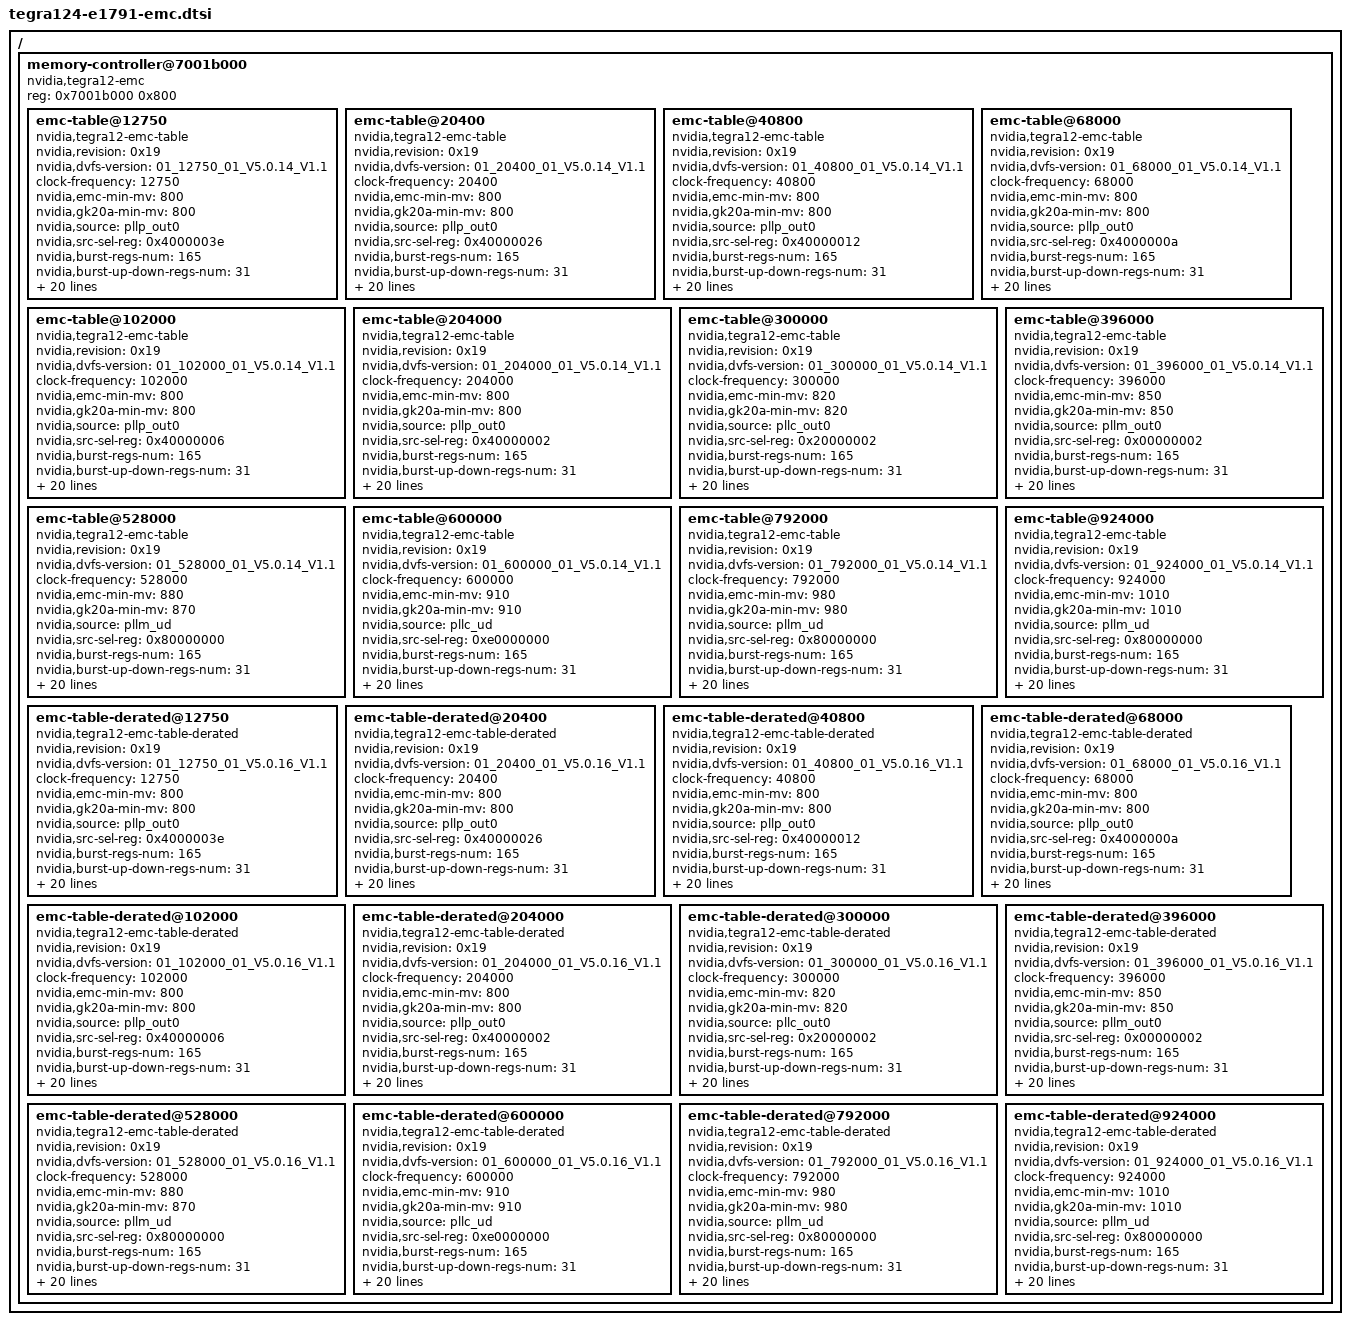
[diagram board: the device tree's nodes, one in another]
/ {
memory-controller@7001b000 {
		compatible = "nvidia,tegra12-emc";
		reg = <0x7001b000 0x800>;
		#address-cells = <1>;
		#size-cells = <0>;
		emc-table@12750 {
			compatible = "nvidia,tegra12-emc-table";
			nvidia,revision = <0x19>;
			nvidia,dvfs-version = "01_12750_01_V5.0.14_V1.1";
			clock-frequency = <12750>;
			nvidia,emc-min-mv = <800>;
			nvidia,gk20a-min-mv = <800>;
			nvidia,source = "pllp_out0";
			nvidia,src-sel-reg = <0x4000003e>;
			nvidia,burst-regs-num = <165>;
			nvidia,burst-up-down-regs-num = <31>;
			nvidia,emc-registers = <
				0x00000000
				0x00000003
				0x00000000
				0x00000002
				0x00000002
				0x00000006
				0x00000008
				0x00000003
				0x0000000a
				0x00000002
				0x00000002
				0x00000001
				0x00000002
				0x00000000
				0x00000003
				0x00000003
				0x00000006
				0x00000002
				0x00000000
				0x00000005
				0x00000005
				0x00010000
				0x00000003
				0x00000000
				0x00000000
				0x00000000
				0x00000000
				0x00000004
				0x0000000c
				0x0000000d
				0x0000000f
				0x00000030
				0x00000000
				0x0000000c
				0x00000002
				0x00000002
				0x00000002
				0x00000000
				0x00000001
				0x0000000c
				0x00000003
				0x00000002
				0x00000003
				0x00000003
				0x00000003
				0x00000006
				0x00000004
				0x00000003
				0x00000003
				0x00000036
				0x00000000
				0x00000000
				0x00000000
				0x1363a296
				0x005800a0
				0x00008000
				0x00048000
				0x00048000
				0x00048000
				0x00048000
				0x00048000
				0x00048000
				0x00048000
				0x00048000
				0x00048000
				0x00048000
				0x00048000
				0x00048000
				0x00048000
				0x00048000
				0x00048000
				0x00048000
				0x00000000
				0x00000000
				0x00000000
				0x00000000
				0x00000000
				0x00000000
				0x00000000
				0x00000000
				0x000fc000
				0x000fc000
				0x00000000
				0x000fc000
				0x000fc000
				0x00000000
				0x00000000
				0x00000000
				0x00000000
				0x00000000
				0x00000000
				0x00000000
				0x00000000
				0x00000000
				0x00000000
				0x00000000
				0x00000000
				0x00000000
				0x00000000
				0x00000000
				0x00000000
				0x00000000
				0x00000000
				0x00000000
				0x00000000
				0x00000000
				0x00000000
				0x00000000
				0x00000000
				0x00000000
				0x000fc000
				0x000fc000
				0x0002c000
				0x000fc000
				0x0000fc00
				0x0000fc00
				0x0000fc00
				0x0000fc00
				0x00000200
				0x00000000
				0x00100100
				0x0130b018
				0x00000000
				0x00000000
				0x77ffc000
				0x00000e0e
				0x81f1f008
				0x07070000
				0x0000003f
				0x015ddddd
				0x51451400
				0x00514514
				0x00514514
				0x51451400
				0x0000003f
				0x00000000
				0x00000000
				0x00064000
				0x00000011
				0x000d0011
				0x000d0011
				0x00000000
				0x00000003
				0x0000f3f3
				0x80000164
				0x0000000a
				0x40040001
				0x8000000a
				0x00000001
				0x00000001
				0x00000002
				0x00000000
				0x00000003
				0x00000001
				0x00000002
				0x00000007
				0x00000002
				0x00000001
				0x00000004
				0x00000005
				0x05040102
				0x00090402
				0x77c30303
				0x70000f03
				0x001f0000
			>;
			nvidia,emc-burst-up-down-regs = <
			0x00000001
			0x00000007
			0x00ff00ff
			0x00ff00ff
			0x00ff00ff
			0x00ff00ff
			0x00ff00ff
			0x00ff00ff
			0x00ff00ff
			0x00ff0049
			0x00ff0080
			0x00ff0004
			0x00ff0004
			0x000800ff
			0x000000ff
			0x00ff0004
			0x00ff00ff
			0x00ff00ff
			0x00ff0024
			0x00ff00ff
			0x000000ff
			0x000000ff
			0x00ff00ff
			0x000000ff
			0x00ff00ff
			0x00ff00ff
			0x00ff00ff
			0x00ff00ff
			0x00ff00ff
			0x00ff00ff
			0x00ff00ff
			>;
			nvidia,emc-zcal-cnt-long = <0x00000015>;
			nvidia,emc-acal-interval = <0x001fffff>;
			nvidia,emc-ctt-term_ctrl = <0x00000802>;
			nvidia,emc-cfg = <0xf3200000>;
			nvidia,emc-cfg-2 = <0x000008c7>;
			nvidia,emc-sel-dpd-ctrl = <0x0004013c>;
			nvidia,emc-cfg-dig-dll = <0x00580068>;
			nvidia,emc-bgbias-ctl0 = <0x00000008>;
			nvidia,emc-auto-cal-config2 = <0x00000000>;
			nvidia,emc-auto-cal-config3 = <0x00000000>;
			nvidia,emc-auto-cal-config = <0xa1430000>;
			nvidia,emc-mode-0 = <0x00000000>;
			nvidia,emc-mode-1 = <0x00010083>;
			nvidia,emc-mode-2 = <0x00020004>;
			nvidia,emc-mode-4 = <0x800b0000>;
			nvidia,emc-clock-latency-change = <57820>;
		};
		emc-table@20400 {
			compatible = "nvidia,tegra12-emc-table";
			nvidia,revision = <0x19>;
			nvidia,dvfs-version = "01_20400_01_V5.0.14_V1.1";
			clock-frequency = <20400>;
			nvidia,emc-min-mv = <800>;
			nvidia,gk20a-min-mv = <800>;
			nvidia,source = "pllp_out0";
			nvidia,src-sel-reg = <0x40000026>;
			nvidia,burst-regs-num = <165>;
			nvidia,burst-up-down-regs-num = <31>;
			nvidia,emc-registers = <
				0x00000001
				0x00000003
				0x00000000
				0x00000002
				0x00000002
				0x00000006
				0x00000008
				0x00000003
				0x0000000a
				0x00000002
				0x00000002
				0x00000001
				0x00000002
				0x00000000
				0x00000003
				0x00000003
				0x00000006
				0x00000002
				0x00000000
				0x00000005
				0x00000005
				0x00010000
				0x00000003
				0x00000000
				0x00000000
				0x00000000
				0x00000000
				0x00000004
				0x0000000c
				0x0000000d
				0x0000000f
				0x0000004d
				0x00000000
				0x00000013
				0x00000002
				0x00000002
				0x00000002
				0x00000000
				0x00000001
				0x0000000c
				0x00000003
				0x00000003
				0x00000003
				0x00000003
				0x00000003
				0x00000006
				0x00000004
				0x00000003
				0x00000003
				0x00000055
				0x00000000
				0x00000000
				0x00000000
				0x1363a296
				0x005800a0
				0x00008000
				0x00048000
				0x00048000
				0x00048000
				0x00048000
				0x00048000
				0x00048000
				0x00048000
				0x00048000
				0x00048000
				0x00048000
				0x00048000
				0x00048000
				0x00048000
				0x00048000
				0x00048000
				0x00048000
				0x00000000
				0x00000000
				0x00000000
				0x00000000
				0x00000000
				0x00000000
				0x00000000
				0x00000000
				0x000fc000
				0x000fc000
				0x00000000
				0x000fc000
				0x000fc000
				0x00000000
				0x00000000
				0x00000000
				0x00000000
				0x00000000
				0x00000000
				0x00000000
				0x00000000
				0x00000000
				0x00000000
				0x00000000
				0x00000000
				0x00000000
				0x00000000
				0x00000000
				0x00000000
				0x00000000
				0x00000000
				0x00000000
				0x00000000
				0x00000000
				0x00000000
				0x00000000
				0x00000000
				0x00000000
				0x000fc000
				0x000fc000
				0x0002c000
				0x000fc000
				0x0000fc00
				0x0000fc00
				0x0000fc00
				0x0000fc00
				0x00000200
				0x00000000
				0x00100100
				0x0130b018
				0x00000000
				0x00000000
				0x77ffc000
				0x00000e0e
				0x81f1f008
				0x07070000
				0x0000003f
				0x015ddddd
				0x51451400
				0x00514514
				0x00514514
				0x51451400
				0x0000003f
				0x00000000
				0x00000000
				0x00064000
				0x00000011
				0x00150011
				0x00150011
				0x00000000
				0x00000003
				0x0000f3f3
				0x8000019f
				0x0000000a
				0x40020001
				0x80000012
				0x00000001
				0x00000001
				0x00000002
				0x00000000
				0x00000003
				0x00000001
				0x00000002
				0x00000007
				0x00000002
				0x00000001
				0x00000004
				0x00000005
				0x05040102
				0x00090402
				0x74e30303
				0x70000f03
				0x001f0000
			>;
			nvidia,emc-burst-up-down-regs = <
			0x00000001
			0x0000000a
			0x00ff00ff
			0x00ff00ff
			0x00ff00ff
			0x00ff00ff
			0x00ff00ff
			0x00ff00ff
			0x00ff00ff
			0x00ff0049
			0x00ff0080
			0x00ff0004
			0x00ff0004
			0x000800ff
			0x000000ff
			0x00ff0004
			0x00ff00ff
			0x00ff00ff
			0x00ff0024
			0x00ff00ff
			0x000000ff
			0x000000ff
			0x00ff00ff
			0x000000ff
			0x00ff00ff
			0x00ff00ff
			0x00ff00ff
			0x00ff00ff
			0x00ff00ff
			0x00ff00ff
			0x00ff00ff
			>;
			nvidia,emc-zcal-cnt-long = <0x00000015>;
			nvidia,emc-acal-interval = <0x001fffff>;
			nvidia,emc-ctt-term_ctrl = <0x00000802>;
			nvidia,emc-cfg = <0xf3200000>;
			nvidia,emc-cfg-2 = <0x000008c7>;
			nvidia,emc-sel-dpd-ctrl = <0x0004013c>;
			nvidia,emc-cfg-dig-dll = <0x00580068>;
			nvidia,emc-bgbias-ctl0 = <0x00000008>;
			nvidia,emc-auto-cal-config2 = <0x00000000>;
			nvidia,emc-auto-cal-config3 = <0x00000000>;
			nvidia,emc-auto-cal-config = <0xa1430000>;
			nvidia,emc-mode-0 = <0x00000000>;
			nvidia,emc-mode-1 = <0x00010083>;
			nvidia,emc-mode-2 = <0x00020004>;
			nvidia,emc-mode-4 = <0x800b0000>;
			nvidia,emc-clock-latency-change = <35610>;
		};
		emc-table@40800 {
			compatible = "nvidia,tegra12-emc-table";
			nvidia,revision = <0x19>;
			nvidia,dvfs-version = "01_40800_01_V5.0.14_V1.1";
			clock-frequency = <40800>;
			nvidia,emc-min-mv = <800>;
			nvidia,gk20a-min-mv = <800>;
			nvidia,source = "pllp_out0";
			nvidia,src-sel-reg = <0x40000012>;
			nvidia,burst-regs-num = <165>;
			nvidia,burst-up-down-regs-num = <31>;
			nvidia,emc-registers = <
				0x00000002
				0x00000005
				0x00000000
				0x00000002
				0x00000002
				0x00000006
				0x00000008
				0x00000003
				0x0000000a
				0x00000002
				0x00000002
				0x00000001
				0x00000002
				0x00000000
				0x00000003
				0x00000003
				0x00000006
				0x00000002
				0x00000000
				0x00000005
				0x00000005
				0x00010000
				0x00000003
				0x00000000
				0x00000000
				0x00000000
				0x00000000
				0x00000004
				0x0000000c
				0x0000000d
				0x0000000f
				0x0000009a
				0x00000000
				0x00000026
				0x00000002
				0x00000002
				0x00000002
				0x00000000
				0x00000001
				0x0000000c
				0x00000006
				0x00000006
				0x00000003
				0x00000003
				0x00000003
				0x00000006
				0x00000004
				0x00000003
				0x00000003
				0x000000aa
				0x00000000
				0x00000000
				0x00000000
				0x1363a296
				0x005800a0
				0x00008000
				0x00048000
				0x00048000
				0x00048000
				0x00048000
				0x00048000
				0x00048000
				0x00048000
				0x00048000
				0x00048000
				0x00048000
				0x00048000
				0x00048000
				0x00048000
				0x00048000
				0x00048000
				0x00048000
				0x00000000
				0x00000000
				0x00000000
				0x00000000
				0x00000000
				0x00000000
				0x00000000
				0x00000000
				0x000fc000
				0x000fc000
				0x00000000
				0x000fc000
				0x000fc000
				0x00000000
				0x00000000
				0x00000000
				0x00000000
				0x00000000
				0x00000000
				0x00000000
				0x00000000
				0x00000000
				0x00000000
				0x00000000
				0x00000000
				0x00000000
				0x00000000
				0x00000000
				0x00000000
				0x00000000
				0x00000000
				0x00000000
				0x00000000
				0x00000000
				0x00000000
				0x00000000
				0x00000000
				0x00000000
				0x000fc000
				0x000fc000
				0x0002c000
				0x000fc000
				0x0000fc00
				0x0000fc00
				0x0000fc00
				0x0000fc00
				0x00000200
				0x00000000
				0x00100100
				0x0130b018
				0x00000000
				0x00000000
				0x77ffc000
				0x00000e0e
				0x81f1f008
				0x07070000
				0x0000003f
				0x015ddddd
				0x51451400
				0x00514514
				0x00514514
				0x51451400
				0x0000003f
				0x00000000
				0x00000000
				0x00064000
				0x00000011
				0x00290011
				0x00290011
				0x00000000
				0x00000003
				0x0000f3f3
				0x8000023a
				0x0000000a
				0xa0000001
				0x80000017
				0x00000001
				0x00000001
				0x00000002
				0x00000000
				0x00000003
				0x00000001
				0x00000002
				0x00000007
				0x00000002
				0x00000001
				0x00000004
				0x00000005
				0x05040102
				0x00090402
				0x73030303
				0x70000f03
				0x001f0000
			>;
			nvidia,emc-burst-up-down-regs = <
			0x00000001
			0x00000014
			0x00ff00ff
			0x00ff00ff
			0x00ff00ff
			0x00ff00ff
			0x00ff00ff
			0x00ff00ff
			0x00ff00ff
			0x00ff0049
			0x00ff0080
			0x00ff0004
			0x00ff0004
			0x000800ff
			0x000000ff
			0x00ff0004
			0x00ff00ff
			0x00ff00ff
			0x00ff0024
			0x00ff00ff
			0x000000ff
			0x000000ff
			0x00ff00ff
			0x000000ff
			0x00ff00ff
			0x00ff00ff
			0x00ff00ff
			0x00ff00ff
			0x00ff00ff
			0x00ff00ff
			0x00ff00ff
			>;
			nvidia,emc-zcal-cnt-long = <0x00000015>;
			nvidia,emc-acal-interval = <0x001fffff>;
			nvidia,emc-ctt-term_ctrl = <0x00000802>;
			nvidia,emc-cfg = <0xf3200000>;
			nvidia,emc-cfg-2 = <0x000008c7>;
			nvidia,emc-sel-dpd-ctrl = <0x0004013c>;
			nvidia,emc-cfg-dig-dll = <0x00580068>;
			nvidia,emc-bgbias-ctl0 = <0x00000008>;
			nvidia,emc-auto-cal-config2 = <0x00000000>;
			nvidia,emc-auto-cal-config3 = <0x00000000>;
			nvidia,emc-auto-cal-config = <0xa1430000>;
			nvidia,emc-mode-0 = <0x00000000>;
			nvidia,emc-mode-1 = <0x00010083>;
			nvidia,emc-mode-2 = <0x00020004>;
			nvidia,emc-mode-4 = <0x800b0000>;
			nvidia,emc-clock-latency-change = <20850>;
		};
		emc-table@68000 {
			compatible = "nvidia,tegra12-emc-table";
			nvidia,revision = <0x19>;
			nvidia,dvfs-version = "01_68000_01_V5.0.14_V1.1";
			clock-frequency = <68000>;
			nvidia,emc-min-mv = <800>;
			nvidia,gk20a-min-mv = <800>;
			nvidia,source = "pllp_out0";
			nvidia,src-sel-reg = <0x4000000a>;
			nvidia,burst-regs-num = <165>;
			nvidia,burst-up-down-regs-num = <31>;
			nvidia,emc-registers = <
				0x00000004
				0x00000008
				0x00000000
				0x00000002
				0x00000002
				0x00000006
				0x00000008
				0x00000003
				0x0000000a
				0x00000002
				0x00000002
				0x00000001
				0x00000002
				0x00000000
				0x00000003
				0x00000003
				0x00000006
				0x00000002
				0x00000000
				0x00000005
				0x00000005
				0x00010000
				0x00000003
				0x00000000
				0x00000000
				0x00000000
				0x00000000
				0x00000004
				0x0000000c
				0x0000000d
				0x0000000f
				0x00000101
				0x00000000
				0x00000040
				0x00000002
				0x00000002
				0x00000002
				0x00000000
				0x00000001
				0x0000000c
				0x0000000a
				0x0000000a
				0x00000003
				0x00000003
				0x00000003
				0x00000006
				0x00000004
				0x00000003
				0x00000003
				0x0000011b
				0x00000000
				0x00000000
				0x00000000
				0x1363a296
				0x005800a0
				0x00008000
				0x00048000
				0x00048000
				0x00048000
				0x00048000
				0x00048000
				0x00048000
				0x00048000
				0x00048000
				0x00048000
				0x00048000
				0x00048000
				0x00048000
				0x00048000
				0x00048000
				0x00048000
				0x00048000
				0x00000000
				0x00000000
				0x00000000
				0x00000000
				0x00000000
				0x00000000
				0x00000000
				0x00000000
				0x000fc000
				0x000fc000
				0x00000000
				0x000fc000
				0x000fc000
				0x00000000
				0x00000000
				0x00000000
				0x00000000
				0x00000000
				0x00000000
				0x00000000
				0x00000000
				0x00000000
				0x00000000
				0x00000000
				0x00000000
				0x00000000
				0x00000000
				0x00000000
				0x00000000
				0x00000000
				0x00000000
				0x00000000
				0x00000000
				0x00000000
				0x00000000
				0x00000000
				0x00000000
				0x00000000
				0x000fc000
				0x000fc000
				0x0002c000
				0x000fc000
				0x0000fc00
				0x0000fc00
				0x0000fc00
				0x0000fc00
				0x00000200
				0x00000000
				0x00100100
				0x0130b018
				0x00000000
				0x00000000
				0x77ffc000
				0x00000e0e
				0x81f1f008
				0x07070000
				0x0000003f
				0x015ddddd
				0x51451400
				0x00514514
				0x00514514
				0x51451400
				0x0000003f
				0x00000000
				0x00000000
				0x00064000
				0x00000019
				0x00440011
				0x00440011
				0x00000000
				0x00000003
				0x0000f3f3
				0x80000309
				0x0000000a
				0x00000001
				0x8000001e
				0x00000001
				0x00000001
				0x00000002
				0x00000000
				0x00000003
				0x00000001
				0x00000002
				0x00000007
				0x00000002
				0x00000001
				0x00000004
				0x00000005
				0x05040102
				0x00090402
				0x72630403
				0x70000f03
				0x001f0000
			>;
			nvidia,emc-burst-up-down-regs = <
			0x00000001
			0x00000021
			0x00ff00ff
			0x00ff00ff
			0x00ff00b0
			0x00ff00ff
			0x00ff00ec
			0x00ff00ff
			0x00ff00ec
			0x00e90049
			0x00ff0080
			0x00ff0004
			0x00ff0004
			0x000800ff
			0x000000ff
			0x00ff0004
			0x00ff00ff
			0x00ff00a3
			0x00ff0024
			0x00ff00ff
			0x000000ff
			0x000000ef
			0x00ff00ff
			0x000000ef
			0x00ff00ff
			0x00ff00ff
			0x00ee00ef
			0x00ff00ff
			0x00ff00ff
			0x00ff00ff
			0x00ff00ff
			>;
			nvidia,emc-zcal-cnt-long = <0x00000015>;
			nvidia,emc-acal-interval = <0x001fffff>;
			nvidia,emc-ctt-term_ctrl = <0x00000802>;
			nvidia,emc-cfg = <0xf3200000>;
			nvidia,emc-cfg-2 = <0x000008c7>;
			nvidia,emc-sel-dpd-ctrl = <0x0004013c>;
			nvidia,emc-cfg-dig-dll = <0x00580068>;
			nvidia,emc-bgbias-ctl0 = <0x00000008>;
			nvidia,emc-auto-cal-config2 = <0x00000000>;
			nvidia,emc-auto-cal-config3 = <0x00000000>;
			nvidia,emc-auto-cal-config = <0xa1430000>;
			nvidia,emc-mode-0 = <0x00000000>;
			nvidia,emc-mode-1 = <0x00010083>;
			nvidia,emc-mode-2 = <0x00020004>;
			nvidia,emc-mode-4 = <0x800b0000>;
			nvidia,emc-clock-latency-change = <10720>;
		};
		emc-table@102000 {
			compatible = "nvidia,tegra12-emc-table";
			nvidia,revision = <0x19>;
			nvidia,dvfs-version = "01_102000_01_V5.0.14_V1.1";
			clock-frequency = <102000>;
			nvidia,emc-min-mv = <800>;
			nvidia,gk20a-min-mv = <800>;
			nvidia,source = "pllp_out0";
			nvidia,src-sel-reg = <0x40000006>;
			nvidia,burst-regs-num = <165>;
			nvidia,burst-up-down-regs-num = <31>;
			nvidia,emc-registers = <
				0x00000006
				0x0000000d
				0x00000000
				0x00000004
				0x00000002
				0x00000006
				0x00000008
				0x00000003
				0x0000000a
				0x00000002
				0x00000002
				0x00000001
				0x00000002
				0x00000000
				0x00000003
				0x00000003
				0x00000006
				0x00000002
				0x00000000
				0x00000005
				0x00000005
				0x00010000
				0x00000003
				0x00000000
				0x00000000
				0x00000000
				0x00000000
				0x00000004
				0x0000000c
				0x0000000d
				0x0000000f
				0x00000182
				0x00000000
				0x00000060
				0x00000002
				0x00000002
				0x00000002
				0x00000000
				0x00000001
				0x0000000c
				0x0000000f
				0x0000000f
				0x00000003
				0x00000003
				0x00000003
				0x00000006
				0x00000004
				0x00000003
				0x00000003
				0x000001a9
				0x00000000
				0x00000000
				0x00000000
				0x1363a296
				0x005800a0
				0x00008000
				0x00048000
				0x00048000
				0x00048000
				0x00048000
				0x00048000
				0x00048000
				0x00048000
				0x00048000
				0x00048000
				0x00048000
				0x00048000
				0x00048000
				0x00048000
				0x00048000
				0x00048000
				0x00048000
				0x00000000
				0x00000000
				0x00000000
				0x00000000
				0x00000000
				0x00000000
				0x00000000
				0x00000000
				0x000fc000
				0x000fc000
				0x00000000
				0x000fc000
				0x000fc000
				0x00000000
				0x00000000
				0x00000000
				0x00000000
				0x00000000
				0x00000000
				0x00000000
				0x00000000
				0x00000000
				0x00000000
				0x00000000
				0x00000000
				0x00000000
				0x00000000
				0x00000000
				0x00000000
				0x00000000
				0x00000000
				0x00000000
				0x00000000
				0x00000000
				0x00000000
				0x00000000
				0x00000000
				0x00000000
				0x000fc000
				0x000fc000
				0x0002c000
				0x000fc000
				0x0000fc00
				0x0000fc00
				0x0000fc00
				0x0000fc00
				0x00000200
				0x00000000
				0x00100100
				0x0130b018
				0x00000000
				0x00000000
				0x77ffc000
				0x00000e0e
				0x81f1f008
				0x07070000
				0x0000003f
				0x015ddddd
				0x51451400
				0x00514514
				0x00514514
				0x51451400
				0x0000003f
				0x00000000
				0x00000000
				0x00064000
				0x00000025
				0x00660011
				0x00660011
				0x00000000
				0x00000003
				0x0000f3f3
				0x8000040b
				0x0000000a
				0x08000001
				0x80000026
				0x00000001
				0x00000001
				0x00000003
				0x00000001
				0x00000003
				0x00000001
				0x00000002
				0x00000007
				0x00000002
				0x00000001
				0x00000004
				0x00000005
				0x05040102
				0x00090403
				0x72430504
				0x70000f03
				0x001f0000
			>;
			nvidia,emc-burst-up-down-regs = <
			0x00000001
			0x00000031
			0x00ff00da
			0x00ff00da
			0x00ff0075
			0x00ff00ff
			0x00ff009d
			0x00ff00ff
			0x00ff009d
			0x009b0049
			0x00ff0080
			0x00ff0004
			0x00ff0004
			0x000800ad
			0x000000ff
			0x00ff0004
			0x00ff00c6
			0x00ff006d
			0x00ff0024
			0x00ff00d6
			0x000000ff
			0x0000009f
			0x00ff00ff
			0x0000009f
			0x00ff00ff
			0x00ff00ff
			0x009f00a0
			0x00ff00ff
			0x00ff00ff
			0x00ff00ff
			0x00ff00da
			>;
			nvidia,emc-zcal-cnt-long = <0x00000015>;
			nvidia,emc-acal-interval = <0x001fffff>;
			nvidia,emc-ctt-term_ctrl = <0x00000802>;
			nvidia,emc-cfg = <0xf3200000>;
			nvidia,emc-cfg-2 = <0x000008c7>;
			nvidia,emc-sel-dpd-ctrl = <0x0004013c>;
			nvidia,emc-cfg-dig-dll = <0x00580068>;
			nvidia,emc-bgbias-ctl0 = <0x00000008>;
			nvidia,emc-auto-cal-config2 = <0x00000000>;
			nvidia,emc-auto-cal-config3 = <0x00000000>;
			nvidia,emc-auto-cal-config = <0xa1430000>;
			nvidia,emc-mode-0 = <0x00000000>;
			nvidia,emc-mode-1 = <0x00010083>;
			nvidia,emc-mode-2 = <0x00020004>;
			nvidia,emc-mode-4 = <0x800b0000>;
			nvidia,emc-clock-latency-change = <6890>;
		};
		emc-table@204000 {
			compatible = "nvidia,tegra12-emc-table";
			nvidia,revision = <0x19>;
			nvidia,dvfs-version = "01_204000_01_V5.0.14_V1.1";
			clock-frequency = <204000>;
			nvidia,emc-min-mv = <800>;
			nvidia,gk20a-min-mv = <800>;
			nvidia,source = "pllp_out0";
			nvidia,src-sel-reg = <0x40000002>;
			nvidia,burst-regs-num = <165>;
			nvidia,burst-up-down-regs-num = <31>;
			nvidia,emc-registers = <
				0x0000000c
				0x0000001a
				0x00000000
				0x00000008
				0x00000003
				0x00000007
				0x00000008
				0x00000003
				0x0000000a
				0x00000003
				0x00000003
				0x00000002
				0x00000003
				0x00000000
				0x00000002
				0x00000002
				0x00000005
				0x00000003
				0x00000000
				0x00000003
				0x00000007
				0x00010000
				0x00000004
				0x00000000
				0x00000000
				0x00000000
				0x00000000
				0x00000002
				0x0000000e
				0x0000000f
				0x00000011
				0x00000304
				0x00000000
				0x000000c1
				0x00000002
				0x00000002
				0x00000003
				0x00000000
				0x00000001
				0x0000000c
				0x0000001d
				0x0000001d
				0x00000003
				0x00000004
				0x00000003
				0x00000009
				0x00000005
				0x00000003
				0x00000003
				0x00000351
				0x00000000
				0x00000000
				0x00000000
				0x1363a296
				0x005800a0
				0x00008000
				0x00048000
				0x00048000
				0x00048000
				0x00048000
				0x00048000
				0x00048000
				0x00048000
				0x00048000
				0x00048000
				0x00048000
				0x00048000
				0x00048000
				0x00048000
				0x00048000
				0x00048000
				0x00048000
				0x00000000
				0x00000000
				0x00000000
				0x00000000
				0x00000000
				0x00000000
				0x00000000
				0x00000000
				0x00070000
				0x00070000
				0x00000000
				0x00070000
				0x00070000
				0x00000000
				0x00000000
				0x00000000
				0x00000000
				0x00000000
				0x00000000
				0x00000000
				0x00000000
				0x00000000
				0x00000000
				0x00000000
				0x00000000
				0x00000000
				0x00000000
				0x00000000
				0x00000000
				0x00000000
				0x00000000
				0x00000000
				0x00000000
				0x00000000
				0x00000000
				0x00000000
				0x00000000
				0x00000000
				0x0008c000
				0x0008c000
				0x00070000
				0x0008c000
				0x00008c00
				0x00008c00
				0x00008800
				0x00009400
				0x00000200
				0x00000000
				0x00100100
				0x0130b018
				0x00000000
				0x00000000
				0x77ffc000
				0x00000202
				0x81f1f008
				0x07070000
				0x0000003f
				0x015ddddd
				0x51451400
				0x00514514
				0x00514514
				0x51451400
				0x0000003f
				0x00000000
				0x00000000
				0x00064000
				0x0000004a
				0x00cc0011
				0x00cc0011
				0x00000000
				0x00000004
				0x0000d3b3
				0x80000713
				0x0000000a
				0x01000003
				0x80000040
				0x00000001
				0x00000001
				0x00000006
				0x00000003
				0x00000005
				0x00000001
				0x00000002
				0x00000007
				0x00000003
				0x00000001
				0x00000005
				0x00000005
				0x05050103
				0x000a0506
				0x71e40a07
				0x70000f03
				0x001f0000
			>;
			nvidia,emc-burst-up-down-regs = <
			0x00000001
			0x00000062
			0x00ff006d
			0x00ff006d
			0x00ff003c
			0x00ff00af
			0x00ff004f
			0x00ff00af
			0x00ff004f
			0x004e0049
			0x00ff0080
			0x00ff0004
			0x00ff0004
			0x00080057
			0x000000ff
			0x00ff0004
			0x00ff0063
			0x00ff0036
			0x00ff0024
			0x00ff006b
			0x000000ff
			0x00000050
			0x00ff00ff
			0x00000050
			0x00ff00ff
			0x00d400ff
			0x00510050
			0x00ff00ff
			0x00ff00ff
			0x00ff00c6
			0x00ff006d
			>;
			nvidia,emc-zcal-cnt-long = <0x00000017>;
			nvidia,emc-acal-interval = <0x001fffff>;
			nvidia,emc-ctt-term_ctrl = <0x00000802>;
			nvidia,emc-cfg = <0xf3200000>;
			nvidia,emc-cfg-2 = <0x000008cf>;
			nvidia,emc-sel-dpd-ctrl = <0x0004013c>;
			nvidia,emc-cfg-dig-dll = <0x00580068>;
			nvidia,emc-bgbias-ctl0 = <0x00000008>;
			nvidia,emc-auto-cal-config2 = <0x00000000>;
			nvidia,emc-auto-cal-config3 = <0x00000000>;
			nvidia,emc-auto-cal-config = <0xa1430000>;
			nvidia,emc-mode-0 = <0x00000000>;
			nvidia,emc-mode-1 = <0x00010083>;
			nvidia,emc-mode-2 = <0x00020004>;
			nvidia,emc-mode-4 = <0x800b0000>;
			nvidia,emc-clock-latency-change = <3420>;
		};
		emc-table@300000 {
			compatible = "nvidia,tegra12-emc-table";
			nvidia,revision = <0x19>;
			nvidia,dvfs-version = "01_300000_01_V5.0.14_V1.1";
			clock-frequency = <300000>;
			nvidia,emc-min-mv = <820>;
			nvidia,gk20a-min-mv = <820>;
			nvidia,source = "pllc_out0";
			nvidia,src-sel-reg = <0x20000002>;
			nvidia,burst-regs-num = <165>;
			nvidia,burst-up-down-regs-num = <31>;
			nvidia,emc-registers = <
				0x00000011
				0x00000026
				0x00000000
				0x0000000c
				0x00000005
				0x00000007
				0x00000008
				0x00000003
				0x0000000a
				0x00000005
				0x00000005
				0x00000002
				0x00000003
				0x00000000
				0x00000002
				0x00000002
				0x00000006
				0x00000003
				0x00000000
				0x00000003
				0x00000008
				0x00030000
				0x00000004
				0x00000000
				0x00000000
				0x00000000
				0x00000000
				0x00000002
				0x0000000f
				0x00000012
				0x00000014
				0x0000046e
				0x00000000
				0x0000011b
				0x00000002
				0x00000002
				0x00000005
				0x00000000
				0x00000001
				0x0000000c
				0x0000002a
				0x0000002a
				0x00000003
				0x00000005
				0x00000003
				0x0000000d
				0x00000007
				0x00000003
				0x00000003
				0x000004e0
				0x00000000
				0x00000000
				0x00000000
				0x1363a096
				0x005800a0
				0x00008000
				0x00000000
				0x00000000
				0x00000000
				0x00000000
				0x00000000
				0x00000000
				0x00000000
				0x00000000
				0x00000000
				0x00000000
				0x00000000
				0x00000000
				0x00000000
				0x00000000
				0x00000000
				0x00000000
				0x00000000
				0x00000000
				0x00000000
				0x00000000
				0x00000000
				0x00000000
				0x00000000
				0x00000000
				0x00058000
				0x00058000
				0x00000000
				0x00058000
				0x00058000
				0x00000000
				0x00000000
				0x00000000
				0x00000000
				0x00000000
				0x00000000
				0x00000000
				0x00000000
				0x00000000
				0x00000000
				0x00000000
				0x00000000
				0x00000000
				0x00000000
				0x00000000
				0x00000000
				0x00000000
				0x00000000
				0x00000000
				0x00000000
				0x00000000
				0x00000000
				0x00000000
				0x00000000
				0x00000000
				0x00040000
				0x00040000
				0x00040000
				0x00040000
				0x00004000
				0x00004000
				0x00004000
				0x00004000
				0x00000200
				0x00000000
				0x00100100
				0x01231239
				0x00000000
				0x00000000
				0x77ffc000
				0x00000202
				0x81f1f008
				0x07070000
				0x0000003f
				0x015ddddd
				0x51451420
				0x00514514
				0x00514514
				0x51451400
				0x0000003f
				0x00000000
				0x00000000
				0x00064000
				0x0000006c
				0x012c0011
				0x012c0011
				0x00000000
				0x00000004
				0x000052a3
				0x800009ed
				0x0000000b
				0x08000004
				0x80000040
				0x00000001
				0x00000002
				0x00000009
				0x00000005
				0x00000007
				0x00000001
				0x00000002
				0x00000007
				0x00000003
				0x00000001
				0x00000005
				0x00000005
				0x05050103
				0x000c0709
				0x71c50e0a
				0x70000f03
				0x001f0000
			>;
			nvidia,emc-burst-up-down-regs = <
			0x00000004
			0x00000090
			0x00ff004a
			0x00ff004a
			0x00ff003c
			0x00ff0090
			0x00ff0041
			0x00ff0090
			0x00ff0041
			0x00350049
			0x00ff0080
			0x00ff0004
			0x00ff0004
			0x0008003b
			0x000000ff
			0x00ff0004
			0x00ff0043
			0x00ff002d
			0x00ff0024
			0x00ff0049
			0x000000ff
			0x00000036
			0x00ff00ff
			0x00000036
			0x00ff00ff
			0x00d400ff
			0x00510036
			0x00ff00ff
			0x00ff00ff
			0x00ff0087
			0x00ff004a
			>;
			nvidia,emc-zcal-cnt-long = <0x0000001f>;
			nvidia,emc-acal-interval = <0x001fffff>;
			nvidia,emc-ctt-term_ctrl = <0x00000802>;
			nvidia,emc-cfg = <0xf3300000>;
			nvidia,emc-cfg-2 = <0x000008d7>;
			nvidia,emc-sel-dpd-ctrl = <0x0004013c>;
			nvidia,emc-cfg-dig-dll = <0x00580068>;
			nvidia,emc-bgbias-ctl0 = <0x00000000>;
			nvidia,emc-auto-cal-config2 = <0x00000000>;
			nvidia,emc-auto-cal-config3 = <0x00000000>;
			nvidia,emc-auto-cal-config = <0xa1430000>;
			nvidia,emc-mode-0 = <0x00000000>;
			nvidia,emc-mode-1 = <0x00010083>;
			nvidia,emc-mode-2 = <0x00020004>;
			nvidia,emc-mode-4 = <0x800b0000>;
			nvidia,emc-clock-latency-change = <2680>;
		};
		emc-table@396000 {
			compatible = "nvidia,tegra12-emc-table";
			nvidia,revision = <0x19>;
			nvidia,dvfs-version = "01_396000_01_V5.0.14_V1.1";
			clock-frequency = <396000>;
			nvidia,emc-min-mv = <850>;
			nvidia,gk20a-min-mv = <850>;
			nvidia,source = "pllm_out0";
			nvidia,src-sel-reg = <0x00000002>;
			nvidia,burst-regs-num = <165>;
			nvidia,burst-up-down-regs-num = <31>;
			nvidia,emc-registers = <
				0x00000017
				0x00000033
				0x00000000
				0x00000010
				0x00000007
				0x00000008
				0x00000008
				0x00000003
				0x0000000a
				0x00000007
				0x00000007
				0x00000003
				0x00000003
				0x00000000
				0x00000002
				0x00000002
				0x00000006
				0x00000003
				0x00000000
				0x00000002
				0x00000009
				0x00030000
				0x00000004
				0x00000000
				0x00000000
				0x00000000
				0x00000000
				0x00000001
				0x00000010
				0x00000012
				0x00000014
				0x000005d9
				0x00000000
				0x00000176
				0x00000002
				0x00000002
				0x00000007
				0x00000000
				0x00000001
				0x0000000e
				0x00000038
				0x00000038
				0x00000003
				0x00000006
				0x00000003
				0x00000012
				0x00000009
				0x00000003
				0x00000003
				0x00000670
				0x00000000
				0x00000000
				0x00000000
				0x1363a096
				0x005800a0
				0x00008000
				0x00000000
				0x00000000
				0x00000000
				0x00000000
				0x00000000
				0x00000000
				0x00000000
				0x00000000
				0x00000000
				0x00000000
				0x00000000
				0x00000000
				0x00000000
				0x00000000
				0x00000000
				0x00000000
				0x00000000
				0x00000000
				0x00000000
				0x00000000
				0x00000000
				0x00000000
				0x00000000
				0x00000000
				0x00060000
				0x00060000
				0x00000000
				0x00060000
				0x00060000
				0x00000000
				0x00000000
				0x00000000
				0x00000000
				0x00000000
				0x00000000
				0x00000000
				0x00000000
				0x00000000
				0x00000000
				0x00000000
				0x00000000
				0x00000000
				0x00000000
				0x00000000
				0x00000000
				0x00000000
				0x00000000
				0x00000000
				0x00000000
				0x00000000
				0x00000000
				0x00000000
				0x00000000
				0x00000000
				0x00038000
				0x00038000
				0x00038000
				0x00038000
				0x00003800
				0x00003800
				0x00003800
				0x00003800
				0x00000200
				0x00000000
				0x00100100
				0x01231239
				0x00000000
				0x00000000
				0x77ffc000
				0x00000202
				0x81f1f008
				0x07070000
				0x0000003f
				0x015ddddd
				0x51451420
				0x00514514
				0x00514514
				0x51451400
				0x0000003f
				0x00000000
				0x00000000
				0x00064000
				0x0000008f
				0x018c0011
				0x018c0011
				0x00000000
				0x00000004
				0x000052a3
				0x80000cc7
				0x0000000b
				0x0f000005
				0x80000040
				0x00000002
				0x00000003
				0x0000000c
				0x00000007
				0x00000009
				0x00000001
				0x00000002
				0x00000007
				0x00000003
				0x00000001
				0x00000005
				0x00000005
				0x05050103
				0x000e090c
				0x71c6120d
				0x70000f03
				0x001f0000
			>;
			nvidia,emc-burst-up-down-regs = <
			0x0000000a
			0x000000be
			0x00ff0038
			0x00ff0038
			0x00ff003c
			0x00ff0090
			0x00ff0041
			0x00ff0090
			0x00ff0041
			0x00280049
			0x00ff0080
			0x00ff0004
			0x00ff0004
			0x0008002d
			0x000000ff
			0x00ff0004
			0x00ff0033
			0x00ff0022
			0x00ff0024
			0x00ff0037
			0x000000ff
			0x00000036
			0x00ff00ff
			0x00000036
			0x00ff00ff
			0x00d400ff
			0x00510029
			0x00ff00ff
			0x00ff00ff
			0x00ff0066
			0x00ff0038
			>;
			nvidia,emc-zcal-cnt-long = <0x00000028>;
			nvidia,emc-acal-interval = <0x001fffff>;
			nvidia,emc-ctt-term_ctrl = <0x00000802>;
			nvidia,emc-cfg = <0xf3300000>;
			nvidia,emc-cfg-2 = <0x00000897>;
			nvidia,emc-sel-dpd-ctrl = <0x0004001c>;
			nvidia,emc-cfg-dig-dll = <0x00580068>;
			nvidia,emc-bgbias-ctl0 = <0x00000000>;
			nvidia,emc-auto-cal-config2 = <0x00000000>;
			nvidia,emc-auto-cal-config3 = <0x00000000>;
			nvidia,emc-auto-cal-config = <0xa1430000>;
			nvidia,emc-mode-0 = <0x00000000>;
			nvidia,emc-mode-1 = <0x00010083>;
			nvidia,emc-mode-2 = <0x00020004>;
			nvidia,emc-mode-4 = <0x800b0000>;
			nvidia,emc-clock-latency-change = <2180>;
		};
		emc-table@528000 {
			compatible = "nvidia,tegra12-emc-table";
			nvidia,revision = <0x19>;
			nvidia,dvfs-version = "01_528000_01_V5.0.14_V1.1";
			clock-frequency = <528000>;
			nvidia,emc-min-mv = <880>;
			nvidia,gk20a-min-mv = <870>;
			nvidia,source = "pllm_ud";
			nvidia,src-sel-reg = <0x80000000>;
			nvidia,burst-regs-num = <165>;
			nvidia,burst-up-down-regs-num = <31>;
			nvidia,emc-registers = <
				0x0000001f
				0x00000044
				0x00000000
				0x00000016
				0x00000009
				0x0000000a
				0x00000009
				0x00000003
				0x0000000d
				0x00000009
				0x00000009
				0x00000005
				0x00000004
				0x00000000
				0x00000002
				0x00000002
				0x00000008
				0x00000003
				0x00000000
				0x00000003
				0x0000000a
				0x00050000
				0x00000004
				0x00000000
				0x00000000
				0x00000000
				0x00000000
				0x00000002
				0x00000011
				0x00000015
				0x00000017
				0x000007cd
				0x00000000
				0x000001f3
				0x00000003
				0x00000003
				0x00000009
				0x00000000
				0x00000001
				0x00000011
				0x0000004a
				0x0000004a
				0x00000004
				0x00000008
				0x00000004
				0x00000019
				0x0000000c
				0x00000003
				0x00000003
				0x00000895
				0x00000000
				0x00000000
				0x00000000
				0x1363a096
				0xe01200b9
				0x00008000
				0x0000000a
				0x0000000a
				0x0000000a
				0x0000000a
				0x0000000a
				0x0000000a
				0x0000000a
				0x0000000a
				0x0000000a
				0x0000000a
				0x0000000a
				0x0000000a
				0x0000000a
				0x0000000a
				0x0000000a
				0x0000000a
				0x00000000
				0x00000000
				0x00000000
				0x00000000
				0x00000000
				0x00000000
				0x00000000
				0x00000000
				0x00000013
				0x00000013
				0x00000000
				0x00004012
				0x00004012
				0x00000000
				0x00000000
				0x00000000
				0x00000000
				0x00000000
				0x00000000
				0x00000000
				0x00000000
				0x00000000
				0x00000000
				0x00000000
				0x00000000
				0x00000000
				0x00000000
				0x00000000
				0x00000000
				0x00000000
				0x00000000
				0x00000000
				0x00000000
				0x00000000
				0x00000000
				0x00000000
				0x00000000
				0x00000000
				0x00000009
				0x00000009
				0x00000009
				0x00000009
				0x00000009
				0x00000009
				0x00000009
				0x00000009
				0x00000220
				0x00000000
				0x00100100
				0x0123123d
				0x00000000
				0x00000000
				0x77ffc004
				0x00000202
				0x81f1f008
				0x07070000
				0x0000003f
				0x015ddddd
				0x51451420
				0x00514514
				0x00514514
				0x51451400
				0x0000003f
				0x00000000
				0x00000000
				0x00064000
				0x000000bf
				0x02100013
				0x02100013
				0x00000000
				0x00000004
				0x000042a0
				0x800010b3
				0x0000000d
				0x0f000007
				0x80000040
				0x00000003
				0x00000004
				0x00000010
				0x0000000a
				0x0000000d
				0x00000002
				0x00000002
				0x00000009
				0x00000003
				0x00000001
				0x00000006
				0x00000006
				0x06060103
				0x00120b10
				0x71c81811
				0x70000f03
				0x001f0000
			>;
			nvidia,emc-burst-up-down-regs = <
			0x0000000d
			0x000000fd
			0x00c10038
			0x00c10038
			0x00c1003c
			0x00c10090
			0x00c10041
			0x00c10090
			0x00c10041
			0x00270049
			0x00c10080
			0x00c10004
			0x00c10004
			0x00080021
			0x000000c1
			0x00c10004
			0x00c10026
			0x00c1001a
			0x00c10024
			0x00c10029
			0x000000c1
			0x00000036
			0x00c100c1
			0x00000036
			0x00c100c1
			0x00d400ff
			0x00510029
			0x00c100c1
			0x00c100c1
			0x00c10065
			0x00c1002a
			>;
			nvidia,emc-zcal-cnt-long = <0x00000034>;
			nvidia,emc-acal-interval = <0x001fffff>;
			nvidia,emc-ctt-term_ctrl = <0x00000802>;
			nvidia,emc-cfg = <0xf3300000>;
			nvidia,emc-cfg-2 = <0x0000089f>;
			nvidia,emc-sel-dpd-ctrl = <0x0004001c>;
			nvidia,emc-cfg-dig-dll = <0xe0120069>;
			nvidia,emc-bgbias-ctl0 = <0x00000000>;
			nvidia,emc-auto-cal-config2 = <0x00000000>;
			nvidia,emc-auto-cal-config3 = <0x00000000>;
			nvidia,emc-auto-cal-config = <0xa1430000>;
			nvidia,emc-mode-0 = <0x00000000>;
			nvidia,emc-mode-1 = <0x000100c3>;
			nvidia,emc-mode-2 = <0x00020006>;
			nvidia,emc-mode-4 = <0x800b0000>;
			nvidia,emc-clock-latency-change = <1440>;
		};
		emc-table@600000 {
			compatible = "nvidia,tegra12-emc-table";
			nvidia,revision = <0x19>;
			nvidia,dvfs-version = "01_600000_01_V5.0.14_V1.1";
			clock-frequency = <600000>;
			nvidia,emc-min-mv = <910>;
			nvidia,gk20a-min-mv = <910>;
			nvidia,source = "pllc_ud";
			nvidia,src-sel-reg = <0xe0000000>;
			nvidia,burst-regs-num = <165>;
			nvidia,burst-up-down-regs-num = <31>;
			nvidia,emc-registers = <
				0x00000023
				0x0000004d
				0x00000000
				0x00000019
				0x0000000a
				0x0000000a
				0x0000000b
				0x00000004
				0x0000000f
				0x0000000a
				0x0000000a
				0x00000005
				0x00000004
				0x00000000
				0x00000004
				0x00000004
				0x0000000a
				0x00000004
				0x00000000
				0x00000003
				0x0000000d
				0x00070000
				0x00000005
				0x00000000
				0x00000000
				0x00000000
				0x00000000
				0x00000002
				0x00000014
				0x00000018
				0x0000001a
				0x000008e4
				0x00000000
				0x00000239
				0x00000004
				0x00000004
				0x0000000a
				0x00000000
				0x00000001
				0x00000013
				0x00000054
				0x00000054
				0x00000005
				0x00000009
				0x00000005
				0x0000001c
				0x0000000d
				0x00000003
				0x00000003
				0x000009c0
				0x00000000
				0x00000000
				0x00000000
				0x1363a096
				0xe00e00b9
				0x00008000
				0x0000000a
				0x0000000a
				0x0000000a
				0x0000000a
				0x0000000a
				0x0000000a
				0x0000000a
				0x0000000a
				0x0000000a
				0x0000000a
				0x0000000a
				0x0000000a
				0x0000000a
				0x0000000a
				0x0000000a
				0x0000000a
				0x00000000
				0x00000000
				0x00000000
				0x00000000
				0x00000000
				0x00000000
				0x00000000
				0x00000000
				0x00000012
				0x00000012
				0x00000000
				0x00000012
				0x00000012
				0x00000000
				0x00000000
				0x00000000
				0x00000000
				0x00000000
				0x00000000
				0x00000000
				0x00000000
				0x00000000
				0x00000000
				0x00000000
				0x00000000
				0x00000000
				0x00000000
				0x00000000
				0x00000000
				0x00000000
				0x00000000
				0x00000000
				0x00000000
				0x00000000
				0x00000000
				0x00000000
				0x00000000
				0x00000000
				0x00000009
				0x00000009
				0x00000009
				0x00000009
				0x00000009
				0x00000009
				0x00000009
				0x00000009
				0x00000220
				0x00000000
				0x00100100
				0x0121103d
				0x00000000
				0x00000000
				0x77ffc004
				0x00000202
				0x81f1f008
				0x07070000
				0x0000003f
				0x015ddddd
				0x49249220
				0x00514514
				0x00514514
				0x49249200
				0x0000003f
				0x00000000
				0x00000000
				0x00064000
				0x000000d8
				0x02580014
				0x02580014
				0x00000000
				0x00000005
				0x000040a0
				0x800012d6
				0x00000010
				0x00000009
				0x80000040
				0x00000004
				0x00000005
				0x00000012
				0x0000000b
				0x0000000e
				0x00000002
				0x00000003
				0x0000000a
				0x00000003
				0x00000001
				0x00000006
				0x00000007
				0x07060103
				0x00140d12
				0x71c91b13
				0x70000f03
				0x001f0000
			>;
			nvidia,emc-burst-up-down-regs = <
			0x0000000f
			0x00000120
			0x00aa0038
			0x00aa0038
			0x00aa003c
			0x00aa0090
			0x00aa0041
			0x00aa0090
			0x00aa0041
			0x00270049
			0x00aa0080
			0x00aa0004
			0x00aa0004
			0x0008001d
			0x000000aa
			0x00aa0004
			0x00aa0022
			0x00aa0018
			0x00aa0024
			0x00aa0024
			0x000000aa
			0x00000036
			0x00aa00aa
			0x00000036
			0x00aa00aa
			0x00d400ff
			0x00510029
			0x00aa00aa
			0x00aa00aa
			0x00aa0065
			0x00aa0025
			>;
			nvidia,emc-zcal-cnt-long = <0x0000003a>;
			nvidia,emc-acal-interval = <0x001fffff>;
			nvidia,emc-ctt-term_ctrl = <0x00000802>;
			nvidia,emc-cfg = <0xf3300000>;
			nvidia,emc-cfg-2 = <0x0000089f>;
			nvidia,emc-sel-dpd-ctrl = <0x0004001c>;
			nvidia,emc-cfg-dig-dll = <0xe00e0069>;
			nvidia,emc-bgbias-ctl0 = <0x00000000>;
			nvidia,emc-auto-cal-config2 = <0x00000000>;
			nvidia,emc-auto-cal-config3 = <0x00000000>;
			nvidia,emc-auto-cal-config = <0xa1430000>;
			nvidia,emc-mode-0 = <0x00000000>;
			nvidia,emc-mode-1 = <0x000100e3>;
			nvidia,emc-mode-2 = <0x00020007>;
			nvidia,emc-mode-4 = <0x800b0000>;
			nvidia,emc-clock-latency-change = <1440>;
		};
		emc-table@792000 {
			compatible = "nvidia,tegra12-emc-table";
			nvidia,revision = <0x19>;
			nvidia,dvfs-version = "01_792000_01_V5.0.14_V1.1";
			clock-frequency = <792000>;
			nvidia,emc-min-mv = <980>;
			nvidia,gk20a-min-mv = <980>;
			nvidia,source = "pllm_ud";
			nvidia,src-sel-reg = <0x80000000>;
			nvidia,burst-regs-num = <165>;
			nvidia,burst-up-down-regs-num = <31>;
			nvidia,emc-registers = <
				0x0000002f
				0x00000066
				0x00000000
				0x00000021
				0x0000000e
				0x0000000d
				0x0000000d
				0x00000005
				0x00000013
				0x0000000e
				0x0000000e
				0x00000007
				0x00000004
				0x00000000
				0x00000005
				0x00000005
				0x0000000e
				0x00000004
				0x00000000
				0x00000005
				0x0000000f
				0x000b0000
				0x00000006
				0x00000000
				0x00000000
				0x00000000
				0x00000000
				0x00000004
				0x00000016
				0x0000001d
				0x0000001f
				0x00000bd1
				0x00000000
				0x000002f4
				0x00000005
				0x00000005
				0x0000000e
				0x00000000
				0x00000001
				0x00000017
				0x0000006f
				0x0000006f
				0x00000006
				0x0000000c
				0x00000006
				0x00000026
				0x00000011
				0x00000003
				0x00000003
				0x00000cdf
				0x00000000
				0x00000000
				0x00000000
				0x1363a096
				0xe00700b9
				0x00008000
				0x00000007
				0x00000006
				0x00000006
				0x00000007
				0x00000008
				0x00000008
				0x00000008
				0x00000008
				0x00000007
				0x00000006
				0x00000006
				0x00000007
				0x00000008
				0x00000008
				0x00000008
				0x00000008
				0x00000000
				0x00000000
				0x00000000
				0x00000000
				0x00000000
				0x00000000
				0x00000000
				0x00000000
				0x00000014
				0x00000014
				0x00000000
				0x00000014
				0x00000014
				0x00000000
				0x00000000
				0x00000000
				0x00000000
				0x00000000
				0x00000000
				0x00000000
				0x00000000
				0x00000000
				0x00000000
				0x00000000
				0x00000000
				0x00000000
				0x00000000
				0x00000000
				0x00000000
				0x00000000
				0x00000000
				0x00000000
				0x00000000
				0x00000000
				0x00000000
				0x00000000
				0x00000000
				0x00000000
				0x00000009
				0x00000009
				0x00000009
				0x00000009
				0x00000009
				0x00000009
				0x00000009
				0x00000009
				0x00000220
				0x00000000
				0x00100100
				0x0120103d
				0x00000000
				0x00000000
				0x77ffc004
				0x00000000
				0x81f1f008
				0x07070000
				0x00000000
				0x015ddddd
				0x51451420
				0x00618618
				0x00618618
				0x51451400
				0x0000003f
				0x00000000
				0x00000000
				0x00064000
				0x0000011e
				0x03180017
				0x03180017
				0x00000000
				0x00000006
				0x00004080
				0x8000188b
				0x00000014
				0x0e00000b
				0x80000040
				0x00000006
				0x00000007
				0x00000018
				0x0000000f
				0x00000013
				0x00000003
				0x00000003
				0x0000000c
				0x00000003
				0x00000001
				0x00000008
				0x00000008
				0x08080103
				0x001a1118
				0x71ac2419
				0x70000f02
				0x001f0000
			>;
			nvidia,emc-burst-up-down-regs = <
			0x00000013
			0x0000017c
			0x00810038
			0x00810038
			0x0081003c
			0x00810090
			0x00810041
			0x00810090
			0x00810041
			0x00270049
			0x00810080
			0x00810004
			0x00810004
			0x00080016
			0x00000081
			0x00810004
			0x00810019
			0x00810018
			0x00810024
			0x0081001c
			0x00000081
			0x00000036
			0x00810081
			0x00000036
			0x00810081
			0x00d400ff
			0x00510029
			0x00810081
			0x00810081
			0x00810065
			0x0081001c
			>;
			nvidia,emc-zcal-cnt-long = <0x0000004c>;
			nvidia,emc-acal-interval = <0x001fffff>;
			nvidia,emc-ctt-term_ctrl = <0x00000802>;
			nvidia,emc-cfg = <0xf3300000>;
			nvidia,emc-cfg-2 = <0x0000089f>;
			nvidia,emc-sel-dpd-ctrl = <0x0004001c>;
			nvidia,emc-cfg-dig-dll = <0xe0070069>;
			nvidia,emc-bgbias-ctl0 = <0x00000000>;
			nvidia,emc-auto-cal-config2 = <0x00000000>;
			nvidia,emc-auto-cal-config3 = <0x00000000>;
			nvidia,emc-auto-cal-config = <0xa1430000>;
			nvidia,emc-mode-0 = <0x00000000>;
			nvidia,emc-mode-1 = <0x00010043>;
			nvidia,emc-mode-2 = <0x0002001a>;
			nvidia,emc-mode-4 = <0x800b0000>;
			nvidia,emc-clock-latency-change = <1200>;
		};
		emc-table@924000 {
			compatible = "nvidia,tegra12-emc-table";
			nvidia,revision = <0x19>;
			nvidia,dvfs-version = "01_924000_01_V5.0.14_V1.1";
			clock-frequency = <924000>;
			nvidia,emc-min-mv = <1010>;
			nvidia,gk20a-min-mv = <1010>;
			nvidia,source = "pllm_ud";
			nvidia,src-sel-reg = <0x80000000>;
			nvidia,burst-regs-num = <165>;
			nvidia,burst-up-down-regs-num = <31>;
			nvidia,emc-registers = <
				0x00000037
				0x00000078
				0x00000000
				0x00000026
				0x00000010
				0x0000000f
				0x00000010
				0x00000006
				0x00000017
				0x00000010
				0x00000010
				0x00000009
				0x00000005
				0x00000000
				0x00000007
				0x00000007
				0x00000010
				0x00000005
				0x00000000
				0x00000005
				0x00000012
				0x000d0000
				0x00000007
				0x00000000
				0x00000000
				0x00000000
				0x00000000
				0x00000004
				0x00000019
				0x00000020
				0x00000022
				0x00000dd4
				0x00000000
				0x00000375
				0x00000006
				0x00000006
				0x00000010
				0x00000000
				0x00000001
				0x0000001b
				0x00000082
				0x00000082
				0x00000007
				0x0000000e
				0x00000007
				0x0000002d
				0x00000014
				0x00000003
				0x00000003
				0x00000f04
				0x00000000
				0x00000000
				0x00000000
				0x1363a896
				0xe00400b9
				0x00008000
				0x00000006
				0x00000008
				0x00000003
				0x00000005
				0x00000007
				0x00000005
				0x00000007
				0x00000007
				0x00000006
				0x00000008
				0x00000003
				0x00000005
				0x00000007
				0x00000005
				0x00000007
				0x00000007
				0x00000000
				0x00000000
				0x00000000
				0x00000000
				0x00000000
				0x00000000
				0x00000000
				0x00000000
				0x00000017
				0x00000017
				0x00000000
				0x00000017
				0x00000017
				0x00000000
				0x00000000
				0x00000000
				0x00000000
				0x00000000
				0x00000000
				0x00000000
				0x00000000
				0x00000000
				0x00000000
				0x00000000
				0x00000000
				0x00000000
				0x00000000
				0x00000000
				0x00000000
				0x00000000
				0x00000000
				0x00000000
				0x00000000
				0x00000000
				0x00000000
				0x00000000
				0x00000000
				0x00000000
				0x00000006
				0x00000006
				0x00000006
				0x00000006
				0x00000006
				0x00000006
				0x00000006
				0x00000006
				0x00000220
				0x00000000
				0x00100100
				0x0120103d
				0x00000000
				0x00000000
				0x77ffc004
				0x00000000
				0x81f1f008
				0x07070000
				0x00000000
				0x015ddddd
				0x5d75d720
				0x00514514
				0x00514514
				0x5d75d700
				0x0000003f
				0x00000000
				0x00000000
				0x00064000
				0x0000014d
				0x039c0019
				0x039c0019
				0x00000000
				0x00000007
				0x00004080
				0x80001c77
				0x00000017
				0x0e00000d
				0x80000040
				0x00000007
				0x00000008
				0x0000001b
				0x00000012
				0x00000017
				0x00000004
				0x00000004
				0x0000000e
				0x00000004
				0x00000001
				0x00000009
				0x00000009
				0x09090104
				0x001e141b
				0x71ae2a1c
				0x70000f02
				0x001f0000
			>;
			nvidia,emc-burst-up-down-regs = <
			0x00000017
			0x000001bb
			0x006e0038
			0x006e0038
			0x006e003c
			0x006e0090
			0x006e0041
			0x006e0090
			0x006e0041
			0x00270049
			0x006e0080
			0x006e0004
			0x006e0004
			0x00080016
			0x0000006e
			0x006e0004
			0x006e0019
			0x006e0018
			0x006e0024
			0x006e001b
			0x0000006e
			0x00000036
			0x006e006e
			0x00000036
			0x006e006e
			0x00d400ff
			0x00510029
			0x006e006e
			0x006e006e
			0x006e0065
			0x006e001c
			>;
			nvidia,emc-zcal-cnt-long = <0x00000058>;
			nvidia,emc-acal-interval = <0x001fffff>;
			nvidia,emc-ctt-term_ctrl = <0x00000802>;
			nvidia,emc-cfg = <0xf3300000>;
			nvidia,emc-cfg-2 = <0x0000089f>;
			nvidia,emc-sel-dpd-ctrl = <0x0004001c>;
			nvidia,emc-cfg-dig-dll = <0xe0040069>;
			nvidia,emc-bgbias-ctl0 = <0x00000000>;
			nvidia,emc-auto-cal-config2 = <0x00000606>;
			nvidia,emc-auto-cal-config3 = <0x00000000>;
			nvidia,emc-auto-cal-config = <0xa1430000>;
			nvidia,emc-mode-0 = <0x00000000>;
			nvidia,emc-mode-1 = <0x00010083>;
			nvidia,emc-mode-2 = <0x0002001c>;
			nvidia,emc-mode-4 = <0x800b0000>;
			nvidia,emc-clock-latency-change = <1180>;
		};
		emc-table-derated@12750 {
			compatible = "nvidia,tegra12-emc-table-derated";
			nvidia,revision = <0x19>;
			nvidia,dvfs-version = "01_12750_01_V5.0.16_V1.1";
			clock-frequency = <12750>;
			nvidia,emc-min-mv = <800>;
			nvidia,gk20a-min-mv = <800>;
			nvidia,source = "pllp_out0";
			nvidia,src-sel-reg = <0x4000003e>;
			nvidia,burst-regs-num = <165>;
			nvidia,burst-up-down-regs-num = <31>;
			nvidia,emc-registers = <
				0x00000000
				0x00000003
				0x00000000
				0x00000002
				0x00000002
				0x00000006
				0x00000008
				0x00000003
				0x0000000a
				0x00000002
				0x00000002
				0x00000001
				0x00000002
				0x00000000
				0x00000003
				0x00000003
				0x00000006
				0x00000002
				0x00000000
				0x00000005
				0x00000005
				0x00010000
				0x00000003
				0x00000000
				0x00000000
				0x00000000
				0x00000000
				0x00000004
				0x0000000c
				0x0000000d
				0x0000000f
				0x0000000b
				0x00000000
				0x00000002
				0x00000002
				0x00000002
				0x00000002
				0x00000000
				0x00000001
				0x0000000c
				0x00000003
				0x00000002
				0x00000003
				0x00000003
				0x00000003
				0x00000006
				0x00000004
				0x00000003
				0x00000003
				0x00000036
				0x00000000
				0x00000000
				0x00000000
				0x1363a296
				0x005800a0
				0x00008000
				0x00048000
				0x00048000
				0x00048000
				0x00048000
				0x00048000
				0x00048000
				0x00048000
				0x00048000
				0x00048000
				0x00048000
				0x00048000
				0x00048000
				0x00048000
				0x00048000
				0x00048000
				0x00048000
				0x00000000
				0x00000000
				0x00000000
				0x00000000
				0x00000000
				0x00000000
				0x00000000
				0x00000000
				0x000fc000
				0x000fc000
				0x00000000
				0x000fc000
				0x000fc000
				0x00000000
				0x00000000
				0x00000000
				0x00000000
				0x00000000
				0x00000000
				0x00000000
				0x00000000
				0x00000000
				0x00000000
				0x00000000
				0x00000000
				0x00000000
				0x00000000
				0x00000000
				0x00000000
				0x00000000
				0x00000000
				0x00000000
				0x00000000
				0x00000000
				0x00000000
				0x00000000
				0x00000000
				0x00000000
				0x000fc000
				0x000fc000
				0x0002c000
				0x000fc000
				0x0000fc00
				0x0000fc00
				0x0000fc00
				0x0000fc00
				0x00000200
				0x00000000
				0x00100100
				0x0130b018
				0x00000000
				0x00000000
				0x77ffc000
				0x00000e0e
				0x81f1f008
				0x07070000
				0x0000003f
				0x015ddddd
				0x51451400
				0x00514514
				0x00514514
				0x51451400
				0x0000003f
				0x00000000
				0x00000000
				0x00064000
				0x00000011
				0x000d0011
				0x000d0011
				0x00000000
				0x00000003
				0x0000f3f3
				0x8000011c
				0x0000000a
				0x40040001
				0x8000000a
				0x00000001
				0x00000001
				0x00000002
				0x00000000
				0x00000003
				0x00000001
				0x00000002
				0x00000007
				0x00000002
				0x00000001
				0x00000004
				0x00000005
				0x05040102
				0x00090402
				0x77c30303
				0x70000f03
				0x001f0000
			>;
			nvidia,emc-burst-up-down-regs = <
			0x00000001
			0x00000007
			0x00ff00ff
			0x00ff00ff
			0x00ff00ff
			0x00ff00ff
			0x00ff00ff
			0x00ff00ff
			0x00ff00ff
			0x00ff0049
			0x00ff0080
			0x00ff0004
			0x00ff0004
			0x000800ff
			0x000000ff
			0x00ff0004
			0x00ff00ff
			0x00ff00ff
			0x00ff0024
			0x00ff00ff
			0x000000ff
			0x000000ff
			0x00ff00ff
			0x000000ff
			0x00ff00ff
			0x00ff00ff
			0x00ff00ff
			0x00ff00ff
			0x00ff00ff
			0x00ff00ff
			0x00ff00ff
			>;
			nvidia,emc-zcal-cnt-long = <0x00000015>;
			nvidia,emc-acal-interval = <0x001fffff>;
			nvidia,emc-ctt-term_ctrl = <0x00000802>;
			nvidia,emc-cfg = <0xf3200000>;
			nvidia,emc-cfg-2 = <0x000008c7>;
			nvidia,emc-sel-dpd-ctrl = <0x0004013c>;
			nvidia,emc-cfg-dig-dll = <0x00580068>;
			nvidia,emc-bgbias-ctl0 = <0x00000008>;
			nvidia,emc-auto-cal-config2 = <0x00000000>;
			nvidia,emc-auto-cal-config3 = <0x00000000>;
			nvidia,emc-auto-cal-config = <0xa1430000>;
			nvidia,emc-mode-0 = <0x00000000>;
			nvidia,emc-mode-1 = <0x00010083>;
			nvidia,emc-mode-2 = <0x00020004>;
			nvidia,emc-mode-4 = <0x800b0000>;
			nvidia,emc-clock-latency-change = <57820>;
		};
		emc-table-derated@20400 {
			compatible = "nvidia,tegra12-emc-table-derated";
			nvidia,revision = <0x19>;
			nvidia,dvfs-version = "01_20400_01_V5.0.16_V1.1";
			clock-frequency = <20400>;
			nvidia,emc-min-mv = <800>;
			nvidia,gk20a-min-mv = <800>;
			nvidia,source = "pllp_out0";
			nvidia,src-sel-reg = <0x40000026>;
			nvidia,burst-regs-num = <165>;
			nvidia,burst-up-down-regs-num = <31>;
			nvidia,emc-registers = <
				0x00000001
				0x00000003
				0x00000000
				0x00000002
				0x00000002
				0x00000006
				0x00000008
				0x00000003
				0x0000000a
				0x00000002
				0x00000002
				0x00000001
				0x00000002
				0x00000000
				0x00000003
				0x00000003
				0x00000006
				0x00000002
				0x00000000
				0x00000005
				0x00000005
				0x00010000
				0x00000003
				0x00000000
				0x00000000
				0x00000000
				0x00000000
				0x00000004
				0x0000000c
				0x0000000d
				0x0000000f
				0x00000013
				0x00000000
				0x00000004
				0x00000002
				0x00000002
				0x00000002
				0x00000000
				0x00000001
				0x0000000c
				0x00000003
				0x00000003
				0x00000003
				0x00000003
				0x00000003
				0x00000006
				0x00000004
				0x00000003
				0x00000003
				0x00000055
				0x00000000
				0x00000000
				0x00000000
				0x1363a296
				0x005800a0
				0x00008000
				0x00048000
				0x00048000
				0x00048000
				0x00048000
				0x00048000
				0x00048000
				0x00048000
				0x00048000
				0x00048000
				0x00048000
				0x00048000
				0x00048000
				0x00048000
				0x00048000
				0x00048000
				0x00048000
				0x00000000
				0x00000000
				0x00000000
				0x00000000
				0x00000000
				0x00000000
				0x00000000
				0x00000000
				0x000fc000
				0x000fc000
				0x00000000
				0x000fc000
				0x000fc000
				0x00000000
				0x00000000
				0x00000000
				0x00000000
				0x00000000
				0x00000000
				0x00000000
				0x00000000
				0x00000000
				0x00000000
				0x00000000
				0x00000000
				0x00000000
				0x00000000
				0x00000000
				0x00000000
				0x00000000
				0x00000000
				0x00000000
				0x00000000
				0x00000000
				0x00000000
				0x00000000
				0x00000000
				0x00000000
				0x000fc000
				0x000fc000
				0x0002c000
				0x000fc000
				0x0000fc00
				0x0000fc00
				0x0000fc00
				0x0000fc00
				0x00000200
				0x00000000
				0x00100100
				0x0130b018
				0x00000000
				0x00000000
				0x77ffc000
				0x00000e0e
				0x81f1f008
				0x07070000
				0x0000003f
				0x015ddddd
				0x51451400
				0x00514514
				0x00514514
				0x51451400
				0x0000003f
				0x00000000
				0x00000000
				0x00064000
				0x00000011
				0x00150011
				0x00150011
				0x00000000
				0x00000003
				0x0000f3f3
				0x8000012a
				0x0000000a
				0x40020001
				0x80000012
				0x00000001
				0x00000001
				0x00000002
				0x00000000
				0x00000003
				0x00000001
				0x00000002
				0x00000007
				0x00000002
				0x00000001
				0x00000004
				0x00000005
				0x05040102
				0x00090402
				0x74e30303
				0x70000f03
				0x001f0000
			>;
			nvidia,emc-burst-up-down-regs = <
			0x00000001
			0x0000000a
			0x00ff00ff
			0x00ff00ff
			0x00ff00ff
			0x00ff00ff
			0x00ff00ff
			0x00ff00ff
			0x00ff00ff
			0x00ff0049
			0x00ff0080
			0x00ff0004
			0x00ff0004
			0x000800ff
			0x000000ff
			0x00ff0004
			0x00ff00ff
			0x00ff00ff
			0x00ff0024
			0x00ff00ff
			0x000000ff
			0x000000ff
			0x00ff00ff
			0x000000ff
			0x00ff00ff
			0x00ff00ff
			0x00ff00ff
			0x00ff00ff
			0x00ff00ff
			0x00ff00ff
			0x00ff00ff
			>;
			nvidia,emc-zcal-cnt-long = <0x00000015>;
			nvidia,emc-acal-interval = <0x001fffff>;
			nvidia,emc-ctt-term_ctrl = <0x00000802>;
			nvidia,emc-cfg = <0xf3200000>;
			nvidia,emc-cfg-2 = <0x000008c7>;
			nvidia,emc-sel-dpd-ctrl = <0x0004013c>;
			nvidia,emc-cfg-dig-dll = <0x00580068>;
			nvidia,emc-bgbias-ctl0 = <0x00000008>;
			nvidia,emc-auto-cal-config2 = <0x00000000>;
			nvidia,emc-auto-cal-config3 = <0x00000000>;
			nvidia,emc-auto-cal-config = <0xa1430000>;
			nvidia,emc-mode-0 = <0x00000000>;
			nvidia,emc-mode-1 = <0x00010083>;
			nvidia,emc-mode-2 = <0x00020004>;
			nvidia,emc-mode-4 = <0x800b0000>;
			nvidia,emc-clock-latency-change = <35610>;
		};
		emc-table-derated@40800 {
			compatible = "nvidia,tegra12-emc-table-derated";
			nvidia,revision = <0x19>;
			nvidia,dvfs-version = "01_40800_01_V5.0.16_V1.1";
			clock-frequency = <40800>;
			nvidia,emc-min-mv = <800>;
			nvidia,gk20a-min-mv = <800>;
			nvidia,source = "pllp_out0";
			nvidia,src-sel-reg = <0x40000012>;
			nvidia,burst-regs-num = <165>;
			nvidia,burst-up-down-regs-num = <31>;
			nvidia,emc-registers = <
				0x00000002
				0x00000005
				0x00000000
				0x00000002
				0x00000002
				0x00000006
				0x00000008
				0x00000003
				0x0000000a
				0x00000002
				0x00000002
				0x00000001
				0x00000002
				0x00000000
				0x00000003
				0x00000003
				0x00000006
				0x00000002
				0x00000000
				0x00000005
				0x00000005
				0x00010000
				0x00000003
				0x00000000
				0x00000000
				0x00000000
				0x00000000
				0x00000004
				0x0000000c
				0x0000000d
				0x0000000f
				0x00000026
				0x00000000
				0x00000009
				0x00000002
				0x00000002
				0x00000002
				0x00000000
				0x00000001
				0x0000000c
				0x00000006
				0x00000006
				0x00000003
				0x00000003
				0x00000003
				0x00000006
				0x00000004
				0x00000003
				0x00000003
				0x000000aa
				0x00000000
				0x00000000
				0x00000000
				0x1363a296
				0x005800a0
				0x00008000
				0x00048000
				0x00048000
				0x00048000
				0x00048000
				0x00048000
				0x00048000
				0x00048000
				0x00048000
				0x00048000
				0x00048000
				0x00048000
				0x00048000
				0x00048000
				0x00048000
				0x00048000
				0x00048000
				0x00000000
				0x00000000
				0x00000000
				0x00000000
				0x00000000
				0x00000000
				0x00000000
				0x00000000
				0x000fc000
				0x000fc000
				0x00000000
				0x000fc000
				0x000fc000
				0x00000000
				0x00000000
				0x00000000
				0x00000000
				0x00000000
				0x00000000
				0x00000000
				0x00000000
				0x00000000
				0x00000000
				0x00000000
				0x00000000
				0x00000000
				0x00000000
				0x00000000
				0x00000000
				0x00000000
				0x00000000
				0x00000000
				0x00000000
				0x00000000
				0x00000000
				0x00000000
				0x00000000
				0x00000000
				0x000fc000
				0x000fc000
				0x0002c000
				0x000fc000
				0x0000fc00
				0x0000fc00
				0x0000fc00
				0x0000fc00
				0x00000200
				0x00000000
				0x00100100
				0x0130b018
				0x00000000
				0x00000000
				0x77ffc000
				0x00000e0e
				0x81f1f008
				0x07070000
				0x0000003f
				0x015ddddd
				0x51451400
				0x00514514
				0x00514514
				0x51451400
				0x0000003f
				0x00000000
				0x00000000
				0x00064000
				0x00000011
				0x00290011
				0x00290011
				0x00000000
				0x00000003
				0x0000f3f3
				0x80000151
				0x0000000a
				0xa0000001
				0x80000017
				0x00000001
				0x00000001
				0x00000002
				0x00000000
				0x00000003
				0x00000001
				0x00000002
				0x00000007
				0x00000002
				0x00000001
				0x00000004
				0x00000005
				0x05040102
				0x00090402
				0x73030303
				0x70000f03
				0x001f0000
			>;
			nvidia,emc-burst-up-down-regs = <
			0x00000001
			0x00000014
			0x00ff00ff
			0x00ff00ff
			0x00ff00ff
			0x00ff00ff
			0x00ff00ff
			0x00ff00ff
			0x00ff00ff
			0x00ff0049
			0x00ff0080
			0x00ff0004
			0x00ff0004
			0x000800ff
			0x000000ff
			0x00ff0004
			0x00ff00ff
			0x00ff00ff
			0x00ff0024
			0x00ff00ff
			0x000000ff
			0x000000ff
			0x00ff00ff
			0x000000ff
			0x00ff00ff
			0x00ff00ff
			0x00ff00ff
			0x00ff00ff
			0x00ff00ff
			0x00ff00ff
			0x00ff00ff
			>;
			nvidia,emc-zcal-cnt-long = <0x00000015>;
			nvidia,emc-acal-interval = <0x001fffff>;
			nvidia,emc-ctt-term_ctrl = <0x00000802>;
			nvidia,emc-cfg = <0xf3200000>;
			nvidia,emc-cfg-2 = <0x000008c7>;
			nvidia,emc-sel-dpd-ctrl = <0x0004013c>;
			nvidia,emc-cfg-dig-dll = <0x00580068>;
			nvidia,emc-bgbias-ctl0 = <0x00000008>;
			nvidia,emc-auto-cal-config2 = <0x00000000>;
			nvidia,emc-auto-cal-config3 = <0x00000000>;
			nvidia,emc-auto-cal-config = <0xa1430000>;
			nvidia,emc-mode-0 = <0x00000000>;
			nvidia,emc-mode-1 = <0x00010083>;
			nvidia,emc-mode-2 = <0x00020004>;
			nvidia,emc-mode-4 = <0x800b0000>;
			nvidia,emc-clock-latency-change = <20850>;
		};
		emc-table-derated@68000 {
			compatible = "nvidia,tegra12-emc-table-derated";
			nvidia,revision = <0x19>;
			nvidia,dvfs-version = "01_68000_01_V5.0.16_V1.1";
			clock-frequency = <68000>;
			nvidia,emc-min-mv = <800>;
			nvidia,gk20a-min-mv = <800>;
			nvidia,source = "pllp_out0";
			nvidia,src-sel-reg = <0x4000000a>;
			nvidia,burst-regs-num = <165>;
			nvidia,burst-up-down-regs-num = <31>;
			nvidia,emc-registers = <
				0x00000004
				0x00000008
				0x00000000
				0x00000002
				0x00000002
				0x00000006
				0x00000008
				0x00000003
				0x0000000a
				0x00000002
				0x00000002
				0x00000001
				0x00000002
				0x00000000
				0x00000003
				0x00000003
				0x00000006
				0x00000002
				0x00000000
				0x00000005
				0x00000005
				0x00010000
				0x00000003
				0x00000000
				0x00000000
				0x00000000
				0x00000000
				0x00000004
				0x0000000c
				0x0000000d
				0x0000000f
				0x00000040
				0x00000000
				0x00000010
				0x00000002
				0x00000002
				0x00000002
				0x00000000
				0x00000001
				0x0000000c
				0x0000000a
				0x0000000a
				0x00000003
				0x00000003
				0x00000003
				0x00000006
				0x00000004
				0x00000003
				0x00000003
				0x0000011b
				0x00000000
				0x00000000
				0x00000000
				0x1363a296
				0x005800a0
				0x00008000
				0x00048000
				0x00048000
				0x00048000
				0x00048000
				0x00048000
				0x00048000
				0x00048000
				0x00048000
				0x00048000
				0x00048000
				0x00048000
				0x00048000
				0x00048000
				0x00048000
				0x00048000
				0x00048000
				0x00000000
				0x00000000
				0x00000000
				0x00000000
				0x00000000
				0x00000000
				0x00000000
				0x00000000
				0x000fc000
				0x000fc000
				0x00000000
				0x000fc000
				0x000fc000
				0x00000000
				0x00000000
				0x00000000
				0x00000000
				0x00000000
				0x00000000
				0x00000000
				0x00000000
				0x00000000
				0x00000000
				0x00000000
				0x00000000
				0x00000000
				0x00000000
				0x00000000
				0x00000000
				0x00000000
				0x00000000
				0x00000000
				0x00000000
				0x00000000
				0x00000000
				0x00000000
				0x00000000
				0x00000000
				0x000fc000
				0x000fc000
				0x0002c000
				0x000fc000
				0x0000fc00
				0x0000fc00
				0x0000fc00
				0x0000fc00
				0x00000200
				0x00000000
				0x00100100
				0x0130b018
				0x00000000
				0x00000000
				0x77ffc000
				0x00000e0e
				0x81f1f008
				0x07070000
				0x0000003f
				0x015ddddd
				0x51451400
				0x00514514
				0x00514514
				0x51451400
				0x0000003f
				0x00000000
				0x00000000
				0x00064000
				0x00000019
				0x00440011
				0x00440011
				0x00000000
				0x00000003
				0x0000f3f3
				0x80000185
				0x0000000a
				0x00000001
				0x8000001e
				0x00000001
				0x00000001
				0x00000002
				0x00000000
				0x00000003
				0x00000001
				0x00000002
				0x00000007
				0x00000002
				0x00000001
				0x00000004
				0x00000005
				0x05040102
				0x00090402
				0x72630403
				0x70000f03
				0x001f0000
			>;
			nvidia,emc-burst-up-down-regs = <
			0x00000001
			0x00000021
			0x00ff00ff
			0x00ff00ff
			0x00ff00b0
			0x00ff00ff
			0x00ff00ec
			0x00ff00ff
			0x00ff00ec
			0x00e90049
			0x00ff0080
			0x00ff0004
			0x00ff0004
			0x000800ff
			0x000000ff
			0x00ff0004
			0x00ff00ff
			0x00ff00a3
			0x00ff0024
			0x00ff00ff
			0x000000ff
			0x000000ef
			0x00ff00ff
			0x000000ef
			0x00ff00ff
			0x00ff00ff
			0x00ee00ef
			0x00ff00ff
			0x00ff00ff
			0x00ff00ff
			0x00ff00ff
			>;
			nvidia,emc-zcal-cnt-long = <0x00000015>;
			nvidia,emc-acal-interval = <0x001fffff>;
			nvidia,emc-ctt-term_ctrl = <0x00000802>;
			nvidia,emc-cfg = <0xf3200000>;
			nvidia,emc-cfg-2 = <0x000008c7>;
			nvidia,emc-sel-dpd-ctrl = <0x0004013c>;
			nvidia,emc-cfg-dig-dll = <0x00580068>;
			nvidia,emc-bgbias-ctl0 = <0x00000008>;
			nvidia,emc-auto-cal-config2 = <0x00000000>;
			nvidia,emc-auto-cal-config3 = <0x00000000>;
			nvidia,emc-auto-cal-config = <0xa1430000>;
			nvidia,emc-mode-0 = <0x00000000>;
			nvidia,emc-mode-1 = <0x00010083>;
			nvidia,emc-mode-2 = <0x00020004>;
			nvidia,emc-mode-4 = <0x800b0000>;
			nvidia,emc-clock-latency-change = <10720>;
		};
		emc-table-derated@102000 {
			compatible = "nvidia,tegra12-emc-table-derated";
			nvidia,revision = <0x19>;
			nvidia,dvfs-version = "01_102000_01_V5.0.16_V1.1";
			clock-frequency = <102000>;
			nvidia,emc-min-mv = <800>;
			nvidia,gk20a-min-mv = <800>;
			nvidia,source = "pllp_out0";
			nvidia,src-sel-reg = <0x40000006>;
			nvidia,burst-regs-num = <165>;
			nvidia,burst-up-down-regs-num = <31>;
			nvidia,emc-registers = <
				0x00000006
				0x0000000d
				0x00000000
				0x00000004
				0x00000002
				0x00000006
				0x00000008
				0x00000003
				0x0000000a
				0x00000002
				0x00000002
				0x00000001
				0x00000002
				0x00000000
				0x00000003
				0x00000003
				0x00000006
				0x00000002
				0x00000000
				0x00000005
				0x00000005
				0x00010000
				0x00000003
				0x00000000
				0x00000000
				0x00000000
				0x00000000
				0x00000004
				0x0000000c
				0x0000000d
				0x0000000f
				0x00000060
				0x00000000
				0x00000018
				0x00000002
				0x00000002
				0x00000002
				0x00000000
				0x00000001
				0x0000000c
				0x0000000f
				0x0000000f
				0x00000003
				0x00000003
				0x00000003
				0x00000006
				0x00000004
				0x00000003
				0x00000003
				0x000001a9
				0x00000000
				0x00000000
				0x00000000
				0x1363a296
				0x005800a0
				0x00008000
				0x00048000
				0x00048000
				0x00048000
				0x00048000
				0x00048000
				0x00048000
				0x00048000
				0x00048000
				0x00048000
				0x00048000
				0x00048000
				0x00048000
				0x00048000
				0x00048000
				0x00048000
				0x00048000
				0x00000000
				0x00000000
				0x00000000
				0x00000000
				0x00000000
				0x00000000
				0x00000000
				0x00000000
				0x000fc000
				0x000fc000
				0x00000000
				0x000fc000
				0x000fc000
				0x00000000
				0x00000000
				0x00000000
				0x00000000
				0x00000000
				0x00000000
				0x00000000
				0x00000000
				0x00000000
				0x00000000
				0x00000000
				0x00000000
				0x00000000
				0x00000000
				0x00000000
				0x00000000
				0x00000000
				0x00000000
				0x00000000
				0x00000000
				0x00000000
				0x00000000
				0x00000000
				0x00000000
				0x00000000
				0x000fc000
				0x000fc000
				0x0002c000
				0x000fc000
				0x0000fc00
				0x0000fc00
				0x0000fc00
				0x0000fc00
				0x00000200
				0x00000000
				0x00100100
				0x0130b018
				0x00000000
				0x00000000
				0x77ffc000
				0x00000e0e
				0x81f1f008
				0x07070000
				0x0000003f
				0x015ddddd
				0x51451400
				0x00514514
				0x00514514
				0x51451400
				0x0000003f
				0x00000000
				0x00000000
				0x00064000
				0x00000025
				0x00660011
				0x00660011
				0x00000000
				0x00000003
				0x0000f3f3
				0x800001c5
				0x0000000a
				0x08000001
				0x80000026
				0x00000001
				0x00000001
				0x00000003
				0x00000001
				0x00000003
				0x00000001
				0x00000002
				0x00000007
				0x00000002
				0x00000001
				0x00000004
				0x00000005
				0x05040102
				0x00090403
				0x72430504
				0x70000f03
				0x001f0000
			>;
			nvidia,emc-burst-up-down-regs = <
			0x00000001
			0x00000031
			0x00ff00da
			0x00ff00da
			0x00ff0075
			0x00ff00ff
			0x00ff009d
			0x00ff00ff
			0x00ff009d
			0x009b0049
			0x00ff0080
			0x00ff0004
			0x00ff0004
			0x000800ad
			0x000000ff
			0x00ff0004
			0x00ff00c6
			0x00ff006d
			0x00ff0024
			0x00ff00d6
			0x000000ff
			0x0000009f
			0x00ff00ff
			0x0000009f
			0x00ff00ff
			0x00ff00ff
			0x009f00a0
			0x00ff00ff
			0x00ff00ff
			0x00ff00ff
			0x00ff00da
			>;
			nvidia,emc-zcal-cnt-long = <0x00000015>;
			nvidia,emc-acal-interval = <0x001fffff>;
			nvidia,emc-ctt-term_ctrl = <0x00000802>;
			nvidia,emc-cfg = <0xf3200000>;
			nvidia,emc-cfg-2 = <0x000008c7>;
			nvidia,emc-sel-dpd-ctrl = <0x0004013c>;
			nvidia,emc-cfg-dig-dll = <0x00580068>;
			nvidia,emc-bgbias-ctl0 = <0x00000008>;
			nvidia,emc-auto-cal-config2 = <0x00000000>;
			nvidia,emc-auto-cal-config3 = <0x00000000>;
			nvidia,emc-auto-cal-config = <0xa1430000>;
			nvidia,emc-mode-0 = <0x00000000>;
			nvidia,emc-mode-1 = <0x00010083>;
			nvidia,emc-mode-2 = <0x00020004>;
			nvidia,emc-mode-4 = <0x800b0000>;
			nvidia,emc-clock-latency-change = <6890>;
		};
		emc-table-derated@204000 {
			compatible = "nvidia,tegra12-emc-table-derated";
			nvidia,revision = <0x19>;
			nvidia,dvfs-version = "01_204000_01_V5.0.16_V1.1";
			clock-frequency = <204000>;
			nvidia,emc-min-mv = <800>;
			nvidia,gk20a-min-mv = <800>;
			nvidia,source = "pllp_out0";
			nvidia,src-sel-reg = <0x40000002>;
			nvidia,burst-regs-num = <165>;
			nvidia,burst-up-down-regs-num = <31>;
			nvidia,emc-registers = <
				0x0000000c
				0x0000001a
				0x00000000
				0x00000008
				0x00000004
				0x00000007
				0x00000008
				0x00000003
				0x0000000a
				0x00000004
				0x00000004
				0x00000002
				0x00000003
				0x00000000
				0x00000002
				0x00000002
				0x00000005
				0x00000003
				0x00000000
				0x00000003
				0x00000007
				0x00010000
				0x00000004
				0x00000000
				0x00000000
				0x00000000
				0x00000000
				0x00000002
				0x0000000e
				0x0000000f
				0x00000011
				0x000000c1
				0x00000000
				0x00000030
				0x00000002
				0x00000002
				0x00000004
				0x00000000
				0x00000001
				0x0000000c
				0x0000001d
				0x0000001d
				0x00000003
				0x00000004
				0x00000003
				0x00000009
				0x00000005
				0x00000003
				0x00000003
				0x00000351
				0x00000000
				0x00000000
				0x00000000
				0x1363a296
				0x005800a0
				0x00008000
				0x00048000
				0x00048000
				0x00048000
				0x00048000
				0x00048000
				0x00048000
				0x00048000
				0x00048000
				0x00048000
				0x00048000
				0x00048000
				0x00048000
				0x00048000
				0x00048000
				0x00048000
				0x00048000
				0x00000000
				0x00000000
				0x00000000
				0x00000000
				0x00000000
				0x00000000
				0x00000000
				0x00000000
				0x00070000
				0x00070000
				0x00000000
				0x00070000
				0x00070000
				0x00000000
				0x00000000
				0x00000000
				0x00000000
				0x00000000
				0x00000000
				0x00000000
				0x00000000
				0x00000000
				0x00000000
				0x00000000
				0x00000000
				0x00000000
				0x00000000
				0x00000000
				0x00000000
				0x00000000
				0x00000000
				0x00000000
				0x00000000
				0x00000000
				0x00000000
				0x00000000
				0x00000000
				0x00000000
				0x0008c000
				0x0008c000
				0x00070000
				0x0008c000
				0x00008c00
				0x00008c00
				0x00008800
				0x00009400
				0x00000200
				0x00000000
				0x00100100
				0x0130b018
				0x00000000
				0x00000000
				0x77ffc000
				0x00000202
				0x81f1f008
				0x07070000
				0x0000003f
				0x015ddddd
				0x51451400
				0x00514514
				0x00514514
				0x51451400
				0x0000003f
				0x00000000
				0x00000000
				0x00064000
				0x0000004a
				0x00cc0011
				0x00cc0011
				0x00000000
				0x00000004
				0x0000d3b3
				0x80000287
				0x0000000a
				0x01000003
				0x80000040
				0x00000001
				0x00000002
				0x00000006
				0x00000003
				0x00000005
				0x00000001
				0x00000002
				0x00000007
				0x00000003
				0x00000001
				0x00000005
				0x00000005
				0x05050103
				0x000b0606
				0x71e40a07
				0x70000f03
				0x001f0000
			>;
			nvidia,emc-burst-up-down-regs = <
			0x00000001
			0x00000062
			0x00ff006d
			0x00ff006d
			0x00ff003c
			0x00ff00af
			0x00ff004f
			0x00ff00af
			0x00ff004f
			0x004e0049
			0x00ff0080
			0x00ff0004
			0x00ff0004
			0x00080057
			0x000000ff
			0x00ff0004
			0x00ff0063
			0x00ff0036
			0x00ff0024
			0x00ff006b
			0x000000ff
			0x00000050
			0x00ff00ff
			0x00000050
			0x00ff00ff
			0x00d400ff
			0x00510050
			0x00ff00ff
			0x00ff00ff
			0x00ff00c6
			0x00ff006d
			>;
			nvidia,emc-zcal-cnt-long = <0x00000017>;
			nvidia,emc-acal-interval = <0x001fffff>;
			nvidia,emc-ctt-term_ctrl = <0x00000802>;
			nvidia,emc-cfg = <0xf3200000>;
			nvidia,emc-cfg-2 = <0x000008cf>;
			nvidia,emc-sel-dpd-ctrl = <0x0004013c>;
			nvidia,emc-cfg-dig-dll = <0x00580068>;
			nvidia,emc-bgbias-ctl0 = <0x00000008>;
			nvidia,emc-auto-cal-config2 = <0x00000000>;
			nvidia,emc-auto-cal-config3 = <0x00000000>;
			nvidia,emc-auto-cal-config = <0xa1430000>;
			nvidia,emc-mode-0 = <0x00000000>;
			nvidia,emc-mode-1 = <0x00010083>;
			nvidia,emc-mode-2 = <0x00020004>;
			nvidia,emc-mode-4 = <0x800b0000>;
			nvidia,emc-clock-latency-change = <3420>;
		};
		emc-table-derated@300000 {
			compatible = "nvidia,tegra12-emc-table-derated";
			nvidia,revision = <0x19>;
			nvidia,dvfs-version = "01_300000_01_V5.0.16_V1.1";
			clock-frequency = <300000>;
			nvidia,emc-min-mv = <820>;
			nvidia,gk20a-min-mv = <820>;
			nvidia,source = "pllc_out0";
			nvidia,src-sel-reg = <0x20000002>;
			nvidia,burst-regs-num = <165>;
			nvidia,burst-up-down-regs-num = <31>;
			nvidia,emc-registers = <
				0x00000012
				0x00000026
				0x00000000
				0x0000000d
				0x00000005
				0x00000007
				0x00000008
				0x00000003
				0x0000000a
				0x00000005
				0x00000005
				0x00000003
				0x00000003
				0x00000000
				0x00000002
				0x00000002
				0x00000006
				0x00000003
				0x00000000
				0x00000003
				0x00000008
				0x00030000
				0x00000004
				0x00000000
				0x00000000
				0x00000000
				0x00000000
				0x00000002
				0x0000000f
				0x00000012
				0x00000014
				0x0000011c
				0x00000000
				0x00000047
				0x00000002
				0x00000002
				0x00000005
				0x00000000
				0x00000001
				0x0000000c
				0x0000002a
				0x0000002a
				0x00000003
				0x00000005
				0x00000003
				0x0000000d
				0x00000007
				0x00000003
				0x00000003
				0x000004e0
				0x00000000
				0x00000000
				0x00000000
				0x1363a096
				0x005800a0
				0x00008000
				0x00000000
				0x00000000
				0x00000000
				0x00000000
				0x00000000
				0x00000000
				0x00000000
				0x00000000
				0x00000000
				0x00000000
				0x00000000
				0x00000000
				0x00000000
				0x00000000
				0x00000000
				0x00000000
				0x00000000
				0x00000000
				0x00000000
				0x00000000
				0x00000000
				0x00000000
				0x00000000
				0x00000000
				0x00058000
				0x00058000
				0x00000000
				0x00058000
				0x00058000
				0x00000000
				0x00000000
				0x00000000
				0x00000000
				0x00000000
				0x00000000
				0x00000000
				0x00000000
				0x00000000
				0x00000000
				0x00000000
				0x00000000
				0x00000000
				0x00000000
				0x00000000
				0x00000000
				0x00000000
				0x00000000
				0x00000000
				0x00000000
				0x00000000
				0x00000000
				0x00000000
				0x00000000
				0x00000000
				0x00040000
				0x00040000
				0x00040000
				0x00040000
				0x00004000
				0x00004000
				0x00004000
				0x00004000
				0x00000200
				0x00000000
				0x00100100
				0x01231239
				0x00000000
				0x00000000
				0x77ffc000
				0x00000202
				0x81f1f008
				0x07070000
				0x0000003f
				0x015ddddd
				0x51451420
				0x00514514
				0x00514514
				0x51451400
				0x0000003f
				0x00000000
				0x00000000
				0x00064000
				0x0000006c
				0x012c0011
				0x012c0011
				0x00000000
				0x00000004
				0x000052a3
				0x8000033e
				0x0000000b
				0x08000004
				0x80000040
				0x00000001
				0x00000002
				0x00000009
				0x00000005
				0x00000007
				0x00000001
				0x00000002
				0x00000007
				0x00000003
				0x00000001
				0x00000005
				0x00000005
				0x05050103
				0x000c0709
				0x71c50e0a
				0x70000f03
				0x001f0000
			>;
			nvidia,emc-burst-up-down-regs = <
			0x00000004
			0x00000090
			0x00ff004a
			0x00ff004a
			0x00ff003c
			0x00ff0090
			0x00ff0041
			0x00ff0090
			0x00ff0041
			0x00350049
			0x00ff0080
			0x00ff0004
			0x00ff0004
			0x0008003b
			0x000000ff
			0x00ff0004
			0x00ff0043
			0x00ff002d
			0x00ff0024
			0x00ff0049
			0x000000ff
			0x00000036
			0x00ff00ff
			0x00000036
			0x00ff00ff
			0x00d400ff
			0x00510036
			0x00ff00ff
			0x00ff00ff
			0x00ff0087
			0x00ff004a
			>;
			nvidia,emc-zcal-cnt-long = <0x0000001f>;
			nvidia,emc-acal-interval = <0x001fffff>;
			nvidia,emc-ctt-term_ctrl = <0x00000802>;
			nvidia,emc-cfg = <0xf3300000>;
			nvidia,emc-cfg-2 = <0x000008d7>;
			nvidia,emc-sel-dpd-ctrl = <0x0004013c>;
			nvidia,emc-cfg-dig-dll = <0x00580068>;
			nvidia,emc-bgbias-ctl0 = <0x00000000>;
			nvidia,emc-auto-cal-config2 = <0x00000000>;
			nvidia,emc-auto-cal-config3 = <0x00000000>;
			nvidia,emc-auto-cal-config = <0xa1430000>;
			nvidia,emc-mode-0 = <0x00000000>;
			nvidia,emc-mode-1 = <0x00010083>;
			nvidia,emc-mode-2 = <0x00020004>;
			nvidia,emc-mode-4 = <0x800b0000>;
			nvidia,emc-clock-latency-change = <2680>;
		};
		emc-table-derated@396000 {
			compatible = "nvidia,tegra12-emc-table-derated";
			nvidia,revision = <0x19>;
			nvidia,dvfs-version = "01_396000_01_V5.0.16_V1.1";
			clock-frequency = <396000>;
			nvidia,emc-min-mv = <850>;
			nvidia,gk20a-min-mv = <850>;
			nvidia,source = "pllm_out0";
			nvidia,src-sel-reg = <0x00000002>;
			nvidia,burst-regs-num = <165>;
			nvidia,burst-up-down-regs-num = <31>;
			nvidia,emc-registers = <
				0x00000018
				0x00000033
				0x00000000
				0x00000011
				0x00000007
				0x00000008
				0x00000008
				0x00000003
				0x0000000a
				0x00000007
				0x00000007
				0x00000004
				0x00000003
				0x00000000
				0x00000002
				0x00000002
				0x00000006
				0x00000003
				0x00000000
				0x00000002
				0x00000009
				0x00030000
				0x00000004
				0x00000000
				0x00000000
				0x00000000
				0x00000000
				0x00000001
				0x00000010
				0x00000012
				0x00000014
				0x00000176
				0x00000000
				0x0000005d
				0x00000002
				0x00000002
				0x00000007
				0x00000000
				0x00000001
				0x0000000e
				0x00000038
				0x00000038
				0x00000003
				0x00000006
				0x00000003
				0x00000012
				0x0000000a
				0x00000003
				0x00000003
				0x00000670
				0x00000000
				0x00000000
				0x00000000
				0x1363a096
				0x005800a0
				0x00008000
				0x00000000
				0x00000000
				0x00000000
				0x00000000
				0x00000000
				0x00000000
				0x00000000
				0x00000000
				0x00000000
				0x00000000
				0x00000000
				0x00000000
				0x00000000
				0x00000000
				0x00000000
				0x00000000
				0x00000000
				0x00000000
				0x00000000
				0x00000000
				0x00000000
				0x00000000
				0x00000000
				0x00000000
				0x00060000
				0x00060000
				0x00000000
				0x00060000
				0x00060000
				0x00000000
				0x00000000
				0x00000000
				0x00000000
				0x00000000
				0x00000000
				0x00000000
				0x00000000
				0x00000000
				0x00000000
				0x00000000
				0x00000000
				0x00000000
				0x00000000
				0x00000000
				0x00000000
				0x00000000
				0x00000000
				0x00000000
				0x00000000
				0x00000000
				0x00000000
				0x00000000
				0x00000000
				0x00000000
				0x00038000
				0x00038000
				0x00038000
				0x00038000
				0x00003800
				0x00003800
				0x00003800
				0x00003800
				0x00000200
				0x00000000
				0x00100100
				0x01231239
				0x00000000
				0x00000000
				0x77ffc000
				0x00000202
				0x81f1f008
				0x07070000
				0x0000003f
				0x015ddddd
				0x51451420
				0x00514514
				0x00514514
				0x51451400
				0x0000003f
				0x00000000
				0x00000000
				0x00064000
				0x0000008f
				0x018c0011
				0x018c0011
				0x00000000
				0x00000004
				0x000052a3
				0x800003f4
				0x0000000b
				0x0f000005
				0x80000040
				0x00000002
				0x00000003
				0x0000000c
				0x00000007
				0x00000009
				0x00000002
				0x00000002
				0x00000007
				0x00000003
				0x00000001
				0x00000005
				0x00000005
				0x05050103
				0x000e090c
				0x71c6120d
				0x70000f03
				0x001f0000
			>;
			nvidia,emc-burst-up-down-regs = <
			0x0000000a
			0x000000be
			0x00ff0038
			0x00ff0038
			0x00ff003c
			0x00ff0090
			0x00ff0041
			0x00ff0090
			0x00ff0041
			0x00280049
			0x00ff0080
			0x00ff0004
			0x00ff0004
			0x0008002d
			0x000000ff
			0x00ff0004
			0x00ff0033
			0x00ff0022
			0x00ff0024
			0x00ff0037
			0x000000ff
			0x00000036
			0x00ff00ff
			0x00000036
			0x00ff00ff
			0x00d400ff
			0x00510029
			0x00ff00ff
			0x00ff00ff
			0x00ff0066
			0x00ff0038
			>;
			nvidia,emc-zcal-cnt-long = <0x00000028>;
			nvidia,emc-acal-interval = <0x001fffff>;
			nvidia,emc-ctt-term_ctrl = <0x00000802>;
			nvidia,emc-cfg = <0xf3300000>;
			nvidia,emc-cfg-2 = <0x00000897>;
			nvidia,emc-sel-dpd-ctrl = <0x0004001c>;
			nvidia,emc-cfg-dig-dll = <0x00580068>;
			nvidia,emc-bgbias-ctl0 = <0x00000000>;
			nvidia,emc-auto-cal-config2 = <0x00000000>;
			nvidia,emc-auto-cal-config3 = <0x00000000>;
			nvidia,emc-auto-cal-config = <0xa1430000>;
			nvidia,emc-mode-0 = <0x00000000>;
			nvidia,emc-mode-1 = <0x00010083>;
			nvidia,emc-mode-2 = <0x00020004>;
			nvidia,emc-mode-4 = <0x800b0000>;
			nvidia,emc-clock-latency-change = <2180>;
		};
		emc-table-derated@528000 {
			compatible = "nvidia,tegra12-emc-table-derated";
			nvidia,revision = <0x19>;
			nvidia,dvfs-version = "01_528000_01_V5.0.16_V1.1";
			clock-frequency = <528000>;
			nvidia,emc-min-mv = <880>;
			nvidia,gk20a-min-mv = <870>;
			nvidia,source = "pllm_ud";
			nvidia,src-sel-reg = <0x80000000>;
			nvidia,burst-regs-num = <165>;
			nvidia,burst-up-down-regs-num = <31>;
			nvidia,emc-registers = <
				0x00000020
				0x00000044
				0x00000000
				0x00000017
				0x0000000a
				0x0000000a
				0x00000009
				0x00000003
				0x0000000d
				0x0000000a
				0x0000000a
				0x00000006
				0x00000004
				0x00000000
				0x00000002
				0x00000002
				0x00000008
				0x00000003
				0x00000000
				0x00000003
				0x0000000a
				0x00050000
				0x00000004
				0x00000000
				0x00000000
				0x00000000
				0x00000000
				0x00000002
				0x00000011
				0x00000015
				0x00000017
				0x000001f3
				0x00000000
				0x0000007c
				0x00000003
				0x00000003
				0x0000000a
				0x00000000
				0x00000001
				0x00000011
				0x0000004a
				0x0000004a
				0x00000004
				0x00000008
				0x00000004
				0x00000019
				0x0000000d
				0x00000003
				0x00000003
				0x00000895
				0x00000000
				0x00000000
				0x00000000
				0x1363a096
				0xe01200b9
				0x00008000
				0x0000000a
				0x0000000a
				0x0000000a
				0x0000000a
				0x0000000a
				0x0000000a
				0x0000000a
				0x0000000a
				0x0000000a
				0x0000000a
				0x0000000a
				0x0000000a
				0x0000000a
				0x0000000a
				0x0000000a
				0x0000000a
				0x00000000
				0x00000000
				0x00000000
				0x00000000
				0x00000000
				0x00000000
				0x00000000
				0x00000000
				0x00000013
				0x00000013
				0x00000000
				0x00004012
				0x00004012
				0x00000000
				0x00000000
				0x00000000
				0x00000000
				0x00000000
				0x00000000
				0x00000000
				0x00000000
				0x00000000
				0x00000000
				0x00000000
				0x00000000
				0x00000000
				0x00000000
				0x00000000
				0x00000000
				0x00000000
				0x00000000
				0x00000000
				0x00000000
				0x00000000
				0x00000000
				0x00000000
				0x00000000
				0x00000000
				0x00000009
				0x00000009
				0x00000009
				0x00000009
				0x00000009
				0x00000009
				0x00000009
				0x00000009
				0x00000220
				0x00000000
				0x00100100
				0x0123123d
				0x00000000
				0x00000000
				0x77ffc004
				0x00000202
				0x81f1f008
				0x07070000
				0x0000003f
				0x015ddddd
				0x51451420
				0x00514514
				0x00514514
				0x51451400
				0x0000003f
				0x00000000
				0x00000000
				0x00064000
				0x000000bf
				0x02100013
				0x02100013
				0x00000000
				0x00000004
				0x000042a0
				0x800004ef
				0x0000000d
				0x0f000007
				0x80000040
				0x00000004
				0x00000005
				0x00000011
				0x0000000a
				0x0000000d
				0x00000003
				0x00000002
				0x00000009
				0x00000003
				0x00000001
				0x00000006
				0x00000006
				0x06060103
				0x00130c11
				0x71c81812
				0x70000f03
				0x001f0000
			>;
			nvidia,emc-burst-up-down-regs = <
			0x0000000d
			0x000000fd
			0x00c10038
			0x00c10038
			0x00c1003c
			0x00c10090
			0x00c10041
			0x00c10090
			0x00c10041
			0x00270049
			0x00c10080
			0x00c10004
			0x00c10004
			0x00080021
			0x000000c1
			0x00c10004
			0x00c10026
			0x00c1001a
			0x00c10024
			0x00c10029
			0x000000c1
			0x00000036
			0x00c100c1
			0x00000036
			0x00c100c1
			0x00d400ff
			0x00510029
			0x00c100c1
			0x00c100c1
			0x00c10065
			0x00c1002a
			>;
			nvidia,emc-zcal-cnt-long = <0x00000034>;
			nvidia,emc-acal-interval = <0x001fffff>;
			nvidia,emc-ctt-term_ctrl = <0x00000802>;
			nvidia,emc-cfg = <0xf3300000>;
			nvidia,emc-cfg-2 = <0x0000089f>;
			nvidia,emc-sel-dpd-ctrl = <0x0004001c>;
			nvidia,emc-cfg-dig-dll = <0xe0120069>;
			nvidia,emc-bgbias-ctl0 = <0x00000000>;
			nvidia,emc-auto-cal-config2 = <0x00000000>;
			nvidia,emc-auto-cal-config3 = <0x00000000>;
			nvidia,emc-auto-cal-config = <0xa1430000>;
			nvidia,emc-mode-0 = <0x00000000>;
			nvidia,emc-mode-1 = <0x000100c3>;
			nvidia,emc-mode-2 = <0x00020006>;
			nvidia,emc-mode-4 = <0x800b0000>;
			nvidia,emc-clock-latency-change = <1440>;
		};
		emc-table-derated@600000 {
			compatible = "nvidia,tegra12-emc-table-derated";
			nvidia,revision = <0x19>;
			nvidia,dvfs-version = "01_600000_01_V5.0.16_V1.1";
			clock-frequency = <600000>;
			nvidia,emc-min-mv = <910>;
			nvidia,gk20a-min-mv = <910>;
			nvidia,source = "pllc_ud";
			nvidia,src-sel-reg = <0xe0000000>;
			nvidia,burst-regs-num = <165>;
			nvidia,burst-up-down-regs-num = <31>;
			nvidia,emc-registers = <
				0x00000025
				0x0000004d
				0x00000000
				0x0000001a
				0x0000000b
				0x0000000a
				0x0000000b
				0x00000004
				0x0000000f
				0x0000000b
				0x0000000b
				0x00000007
				0x00000004
				0x00000000
				0x00000004
				0x00000004
				0x0000000a
				0x00000004
				0x00000000
				0x00000003
				0x0000000d
				0x00070000
				0x00000005
				0x00000000
				0x00000000
				0x00000000
				0x00000000
				0x00000002
				0x00000014
				0x00000018
				0x0000001a
				0x00000237
				0x00000000
				0x0000008d
				0x00000004
				0x00000004
				0x0000000b
				0x00000000
				0x00000001
				0x00000013
				0x00000054
				0x00000054
				0x00000005
				0x00000009
				0x00000005
				0x0000001c
				0x0000000e
				0x00000003
				0x00000003
				0x000009c0
				0x00000000
				0x00000000
				0x00000000
				0x1363a096
				0xe00e00b9
				0x00008000
				0x0000000a
				0x0000000a
				0x0000000a
				0x0000000a
				0x0000000a
				0x0000000a
				0x0000000a
				0x0000000a
				0x0000000a
				0x0000000a
				0x0000000a
				0x0000000a
				0x0000000a
				0x0000000a
				0x0000000a
				0x0000000a
				0x00000000
				0x00000000
				0x00000000
				0x00000000
				0x00000000
				0x00000000
				0x00000000
				0x00000000
				0x00000012
				0x00000012
				0x00000000
				0x00000012
				0x00000012
				0x00000000
				0x00000000
				0x00000000
				0x00000000
				0x00000000
				0x00000000
				0x00000000
				0x00000000
				0x00000000
				0x00000000
				0x00000000
				0x00000000
				0x00000000
				0x00000000
				0x00000000
				0x00000000
				0x00000000
				0x00000000
				0x00000000
				0x00000000
				0x00000000
				0x00000000
				0x00000000
				0x00000000
				0x00000000
				0x00000009
				0x00000009
				0x00000009
				0x00000009
				0x00000009
				0x00000009
				0x00000009
				0x00000009
				0x00000220
				0x00000000
				0x00100100
				0x0121103d
				0x00000000
				0x00000000
				0x77ffc004
				0x00000202
				0x81f1f008
				0x07070000
				0x0000003f
				0x015ddddd
				0x49249220
				0x00514514
				0x00514514
				0x49249200
				0x0000003f
				0x00000000
				0x00000000
				0x00064000
				0x000000d8
				0x02580014
				0x02580014
				0x00000000
				0x00000005
				0x000040a0
				0x80000578
				0x00000010
				0x00000009
				0x80000040
				0x00000004
				0x00000005
				0x00000013
				0x0000000c
				0x0000000e
				0x00000003
				0x00000003
				0x0000000a
				0x00000003
				0x00000001
				0x00000006
				0x00000007
				0x07060103
				0x00150e13
				0x71c91b14
				0x70000f03
				0x001f0000
			>;
			nvidia,emc-burst-up-down-regs = <
			0x0000000f
			0x00000120
			0x00aa0038
			0x00aa0038
			0x00aa003c
			0x00aa0090
			0x00aa0041
			0x00aa0090
			0x00aa0041
			0x00270049
			0x00aa0080
			0x00aa0004
			0x00aa0004
			0x0008001d
			0x000000aa
			0x00aa0004
			0x00aa0022
			0x00aa0018
			0x00aa0024
			0x00aa0024
			0x000000aa
			0x00000036
			0x00aa00aa
			0x00000036
			0x00aa00aa
			0x00d400ff
			0x00510029
			0x00aa00aa
			0x00aa00aa
			0x00aa0065
			0x00aa0025
			>;
			nvidia,emc-zcal-cnt-long = <0x0000003a>;
			nvidia,emc-acal-interval = <0x001fffff>;
			nvidia,emc-ctt-term_ctrl = <0x00000802>;
			nvidia,emc-cfg = <0xf3300000>;
			nvidia,emc-cfg-2 = <0x0000089f>;
			nvidia,emc-sel-dpd-ctrl = <0x0004001c>;
			nvidia,emc-cfg-dig-dll = <0xe00e0069>;
			nvidia,emc-bgbias-ctl0 = <0x00000000>;
			nvidia,emc-auto-cal-config2 = <0x00000000>;
			nvidia,emc-auto-cal-config3 = <0x00000000>;
			nvidia,emc-auto-cal-config = <0xa1430000>;
			nvidia,emc-mode-0 = <0x00000000>;
			nvidia,emc-mode-1 = <0x000100e3>;
			nvidia,emc-mode-2 = <0x00020007>;
			nvidia,emc-mode-4 = <0x800b0000>;
			nvidia,emc-clock-latency-change = <1440>;
		};
		emc-table-derated@792000 {
			compatible = "nvidia,tegra12-emc-table-derated";
			nvidia,revision = <0x19>;
			nvidia,dvfs-version = "01_792000_01_V5.0.16_V1.1";
			clock-frequency = <792000>;
			nvidia,emc-min-mv = <980>;
			nvidia,gk20a-min-mv = <980>;
			nvidia,source = "pllm_ud";
			nvidia,src-sel-reg = <0x80000000>;
			nvidia,burst-regs-num = <165>;
			nvidia,burst-up-down-regs-num = <31>;
			nvidia,emc-registers = <
				0x00000030
				0x00000066
				0x00000000
				0x00000022
				0x0000000f
				0x0000000e
				0x0000000d
				0x00000005
				0x00000013
				0x0000000f
				0x0000000f
				0x00000009
				0x00000004
				0x00000000
				0x00000005
				0x00000005
				0x0000000e
				0x00000004
				0x00000000
				0x00000005
				0x0000000f
				0x000b0000
				0x00000006
				0x00000000
				0x00000000
				0x00000000
				0x00000000
				0x00000004
				0x00000016
				0x0000001d
				0x0000001f
				0x000002ec
				0x00000000
				0x000000bb
				0x00000005
				0x00000005
				0x0000000f
				0x00000000
				0x00000001
				0x00000017
				0x0000006f
				0x0000006f
				0x00000006
				0x0000000c
				0x00000006
				0x00000026
				0x00000013
				0x00000003
				0x00000003
				0x00000cdf
				0x00000000
				0x00000000
				0x00000000
				0x1363a096
				0xe00700b9
				0x00008000
				0x00000007
				0x00000006
				0x00000006
				0x00000007
				0x00000008
				0x00000008
				0x00000008
				0x00000008
				0x00000007
				0x00000006
				0x00000006
				0x00000007
				0x00000008
				0x00000008
				0x00000008
				0x00000008
				0x00000000
				0x00000000
				0x00000000
				0x00000000
				0x00000000
				0x00000000
				0x00000000
				0x00000000
				0x00000014
				0x00000014
				0x00000000
				0x00000014
				0x00000014
				0x00000000
				0x00000000
				0x00000000
				0x00000000
				0x00000000
				0x00000000
				0x00000000
				0x00000000
				0x00000000
				0x00000000
				0x00000000
				0x00000000
				0x00000000
				0x00000000
				0x00000000
				0x00000000
				0x00000000
				0x00000000
				0x00000000
				0x00000000
				0x00000000
				0x00000000
				0x00000000
				0x00000000
				0x00000000
				0x00000009
				0x00000009
				0x00000009
				0x00000009
				0x00000009
				0x00000009
				0x00000009
				0x00000009
				0x00000220
				0x00000000
				0x00100100
				0x0120103d
				0x00000000
				0x00000000
				0x77ffc004
				0x00000000
				0x81f1f008
				0x07070000
				0x00000000
				0x015ddddd
				0x51451420
				0x00618618
				0x00618618
				0x51451400
				0x0000003f
				0x00000000
				0x00000000
				0x00064000
				0x0000011e
				0x03180017
				0x03180017
				0x00000000
				0x00000006
				0x00004080
				0x800006e5
				0x00000014
				0x0e00000b
				0x80000040
				0x00000006
				0x00000007
				0x00000019
				0x00000010
				0x00000013
				0x00000004
				0x00000003
				0x0000000c
				0x00000003
				0x00000001
				0x00000008
				0x00000008
				0x08080103
				0x001b1219
				0x71ac241a
				0x70000f02
				0x001f0000
			>;
			nvidia,emc-burst-up-down-regs = <
			0x00000013
			0x0000017c
			0x00810038
			0x00810038
			0x0081003c
			0x00810090
			0x00810041
			0x00810090
			0x00810041
			0x00270049
			0x00810080
			0x00810004
			0x00810004
			0x00080016
			0x00000081
			0x00810004
			0x00810019
			0x00810018
			0x00810024
			0x0081001c
			0x00000081
			0x00000036
			0x00810081
			0x00000036
			0x00810081
			0x00d400ff
			0x00510029
			0x00810081
			0x00810081
			0x00810065
			0x0081001c
			>;
			nvidia,emc-zcal-cnt-long = <0x0000004c>;
			nvidia,emc-acal-interval = <0x001fffff>;
			nvidia,emc-ctt-term_ctrl = <0x00000802>;
			nvidia,emc-cfg = <0xf3300000>;
			nvidia,emc-cfg-2 = <0x0000089f>;
			nvidia,emc-sel-dpd-ctrl = <0x0004001c>;
			nvidia,emc-cfg-dig-dll = <0xe0070069>;
			nvidia,emc-bgbias-ctl0 = <0x00000000>;
			nvidia,emc-auto-cal-config2 = <0x00000000>;
			nvidia,emc-auto-cal-config3 = <0x00000000>;
			nvidia,emc-auto-cal-config = <0xa1430000>;
			nvidia,emc-mode-0 = <0x00000000>;
			nvidia,emc-mode-1 = <0x00010043>;
			nvidia,emc-mode-2 = <0x0002001a>;
			nvidia,emc-mode-4 = <0x800b0000>;
			nvidia,emc-clock-latency-change = <1200>;
		};
		emc-table-derated@924000 {
			compatible = "nvidia,tegra12-emc-table-derated";
			nvidia,revision = <0x19>;
			nvidia,dvfs-version = "01_924000_01_V5.0.16_V1.1";
			clock-frequency = <924000>;
			nvidia,emc-min-mv = <1010>;
			nvidia,gk20a-min-mv = <1010>;
			nvidia,source = "pllm_ud";
			nvidia,src-sel-reg = <0x80000000>;
			nvidia,burst-regs-num = <165>;
			nvidia,burst-up-down-regs-num = <31>;
			nvidia,emc-registers = <
				0x00000039
				0x00000078
				0x00000000
				0x00000028
				0x00000012
				0x00000010
				0x00000010
				0x00000006
				0x00000017
				0x00000012
				0x00000012
				0x0000000a
				0x00000005
				0x00000000
				0x00000007
				0x00000007
				0x00000010
				0x00000005
				0x00000000
				0x00000005
				0x00000012
				0x000d0000
				0x00000007
				0x00000000
				0x00000000
				0x00000000
				0x00000000
				0x00000004
				0x00000019
				0x00000020
				0x00000022
				0x00000369
				0x00000000
				0x000000da
				0x00000006
				0x00000006
				0x00000012
				0x00000000
				0x00000001
				0x0000001b
				0x00000082
				0x00000082
				0x00000007
				0x0000000e
				0x00000007
				0x0000002d
				0x00000016
				0x00000003
				0x00000003
				0x00000f04
				0x00000000
				0x00000000
				0x00000000
				0x1363a896
				0xe00400b9
				0x00008000
				0x00000006
				0x00000008
				0x00000003
				0x00000005
				0x00000007
				0x00000005
				0x00000007
				0x00000007
				0x00000006
				0x00000008
				0x00000003
				0x00000005
				0x00000007
				0x00000005
				0x00000007
				0x00000007
				0x00000000
				0x00000000
				0x00000000
				0x00000000
				0x00000000
				0x00000000
				0x00000000
				0x00000000
				0x00000017
				0x00000017
				0x00000000
				0x00000017
				0x00000017
				0x00000000
				0x00000000
				0x00000000
				0x00000000
				0x00000000
				0x00000000
				0x00000000
				0x00000000
				0x00000000
				0x00000000
				0x00000000
				0x00000000
				0x00000000
				0x00000000
				0x00000000
				0x00000000
				0x00000000
				0x00000000
				0x00000000
				0x00000000
				0x00000000
				0x00000000
				0x00000000
				0x00000000
				0x00000000
				0x00000006
				0x00000006
				0x00000006
				0x00000006
				0x00000006
				0x00000006
				0x00000006
				0x00000006
				0x00000220
				0x00000000
				0x00100100
				0x0120103d
				0x00000000
				0x00000000
				0x77ffc004
				0x00000000
				0x81f1f008
				0x07070000
				0x00000000
				0x015ddddd
				0x5d75d720
				0x00514514
				0x00514514
				0x5d75d700
				0x0000003f
				0x00000000
				0x00000000
				0x00064000
				0x0000014d
				0x039c0019
				0x039c0019
				0x00000000
				0x00000007
				0x00004080
				0x800007e0
				0x00000017
				0x0e00000d
				0x80000040
				0x00000008
				0x00000009
				0x0000001d
				0x00000013
				0x00000017
				0x00000005
				0x00000004
				0x0000000e
				0x00000004
				0x00000001
				0x00000009
				0x00000009
				0x09090104
				0x0020161d
				0x71ae2a1e
				0x70000f02
				0x001f0000
			>;
			nvidia,emc-burst-up-down-regs = <
			0x00000017
			0x000001bb
			0x006e0038
			0x006e0038
			0x006e003c
			0x006e0090
			0x006e0041
			0x006e0090
			0x006e0041
			0x00270049
			0x006e0080
			0x006e0004
			0x006e0004
			0x00080016
			0x0000006e
			0x006e0004
			0x006e0019
			0x006e0018
			0x006e0024
			0x006e001b
			0x0000006e
			0x00000036
			0x006e006e
			0x00000036
			0x006e006e
			0x00d400ff
			0x00510029
			0x006e006e
			0x006e006e
			0x006e0065
			0x006e001c
			>;
			nvidia,emc-zcal-cnt-long = <0x00000058>;
			nvidia,emc-acal-interval = <0x001fffff>;
			nvidia,emc-ctt-term_ctrl = <0x00000802>;
			nvidia,emc-cfg = <0xf3300000>;
			nvidia,emc-cfg-2 = <0x0000089f>;
			nvidia,emc-sel-dpd-ctrl = <0x0004001c>;
			nvidia,emc-cfg-dig-dll = <0xe0040069>;
			nvidia,emc-bgbias-ctl0 = <0x00000000>;
			nvidia,emc-auto-cal-config2 = <0x00000606>;
			nvidia,emc-auto-cal-config3 = <0x00000000>;
			nvidia,emc-auto-cal-config = <0xa1430000>;
			nvidia,emc-mode-0 = <0x00000000>;
			nvidia,emc-mode-1 = <0x00010083>;
			nvidia,emc-mode-2 = <0x0002001c>;
			nvidia,emc-mode-4 = <0x800b0000>;
			nvidia,emc-clock-latency-change = <1180>;
		};
	};
};
